VERSION "created by canmatrix"

NS_ :

BS_:

BU_: TBOX FC_Public VCU GW APA

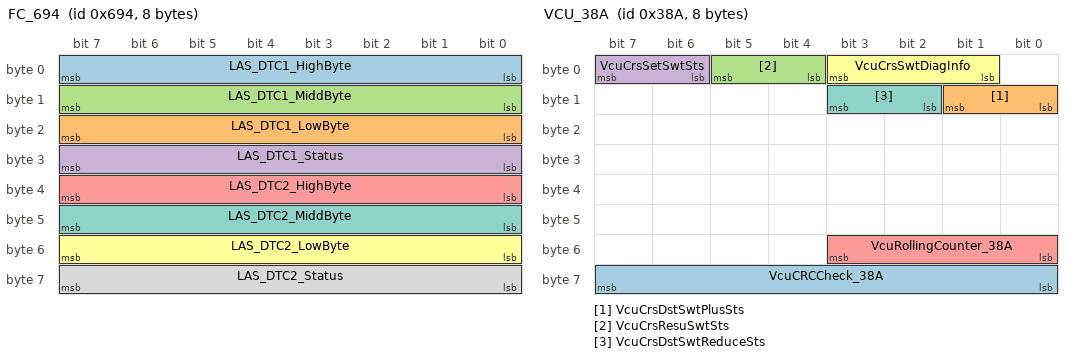
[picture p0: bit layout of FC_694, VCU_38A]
BO_ 1684 FC_694: 8 FC_Public
 SG_ LAS_DTC1_HighByte : 7|8@0+ (1,0) [0|255] "" TBOX
 SG_ LAS_DTC1_LowByte : 23|8@0+ (1,0) [0|255] "" TBOX
 SG_ LAS_DTC1_MiddByte : 15|8@0+ (1,0) [0|255] "" TBOX
 SG_ LAS_DTC1_Status : 31|8@0+ (1,0) [0|255] "" TBOX
 SG_ LAS_DTC2_HighByte : 39|8@0+ (1,0) [0|255] "" TBOX
 SG_ LAS_DTC2_LowByte : 55|8@0+ (1,0) [0|255] "" TBOX
 SG_ LAS_DTC2_MiddByte : 47|8@0+ (1,0) [0|255] "" TBOX
 SG_ LAS_DTC2_Status : 63|8@0+ (1,0) [0|255] "" TBOX

BO_ 759 TBOX_2F7: 64 TBOX
 SG_ TboxLocalTiDate : 20|5@0+ (1,0) [0|31] "day" FC_Public
 SG_ TboxLocalTiHr : 28|5@0+ (1,0) [0|31] "hour" FC_Public
 SG_ TboxLocalTiMins : 37|6@0+ (1,0) [0|63] "minute" FC_Public
 SG_ TboxLocalTiMth : 11|4@0+ (1,0) [0|15] "month" FC_Public
 SG_ TboxLocalTiSec : 45|6@0+ (1,0) [0|63] "second" FC_Public
 SG_ TboxLocalTiVld : 46|1@0+ (1,0) [0|1] "" FC_Public
 SG_ TboxLocalTiYear : 7|8@0+ (1,2000) [2000|2255] "year" FC_Public

BO_ 353 VCU_161: 64 VCU
 SG_ VCUAccPedShield : 7|1@0+ (1,0) [0|1] "" FC_Public
 SG_ VCUAPAdriverInterruption : 6|2@0+ (1,0) [0|3] "" FC_Public
 SG_ VCUAPARequestEnable : 4|2@0+ (1,0) [0|3] "" FC_Public
 SG_ VCUShiftPostionValid : 2|1@0+ (1,0) [0|1] "" FC_Public
 SG_ VcuAccrMod : 1|3@0+ (1,0) [0|7] "" FC_Public
 SG_ VcuAccrPedlPosn : 14|10@0+ (0.1,0) [0|102.3] "%" FC_Public
 SG_ VcuAccrPedlPosnVld : 20|1@0+ (1,0) [0|1] "" FC_Public
 SG_ VcuAPATorqRequestAvailable : 19|1@0+ (1,0) [0|1] "" FC_Public
 SG_ VcuCalcnAccrPedlPosn : 18|10@0+ (0.1,0) [0|102.3] "%" FC_Public
 SG_ VcuCalcnAccrPedlPosnVld : 24|1@0+ (1,0) [0|1] "" FC_Public
 SG_ VcuComFltSts : 39|2@0+ (1,0) [0|3] "" FC_Public
 SG_ VcuEnyRecyclMod : 37|7@0+ (1,0) [0|127] "" FC_Public
 SG_ VcuGearPosn : 65|3@0+ (1,0) [0|7] "" FC_Public
 SG_ VcuOvrdModReq : 78|1@0+ (1,0) [0|1] "" FC_Public
 SG_ VcuPtTqLimMax : 87|16@0+ (1,-32768) [-32768|32767] "Nm" FC_Public
 SG_ VcuPtTqLimMaxVld : 77|1@0+ (1,0) [0|1] "" FC_Public
 SG_ VcuPtTqLimMin : 103|16@0+ (1,-32768) [-32768|32767] "Nm" FC_Public
 SG_ VcuPtTqLimMinVld : 76|1@0+ (1,0) [0|1] "" FC_Public
 SG_ VcuPtTqReal : 135|16@0+ (1,-32768) [-32768|32767] "Nm" FC_Public
 SG_ VcuPtTqRealVld : 75|1@0+ (1,0) [0|1] "" FC_Public
 SG_ VcuPtTqReqAvl : 74|2@0+ (1,0) [0|3] "" FC_Public
 SG_ VcuRdySts : 151|1@0+ (1,0) [0|1] "" FC_Public
 SG_ VcuShiftLvlPosn : 119|4@0+ (1,0) [0|15] "" FC_Public
 SG_ VcuVehGearPosnVld : 150|1@0+ (1,0) [0|1] "" FC_Public
 SG_ VcuVehWhlReqTq : 159|16@0+ (1,-32768) [-32768|32767] "Nm" FC_Public
 SG_ VcuVehWhlReqTqVld : 149|1@0+ (1,0) [0|1] "" FC_Public
 SG_ VcuCrcChk161 : 503|16@0+ (1,0) [0|65535] "" FC_Public
 SG_ VcuCycCntr161 : 491|4@0+ (1,0) [0|15] "" FC_Public

BO_ 906 VCU_38A: 8 VCU
 SG_ VcuCRCCheck_38A : 63|8@0+ (1,0) [0|255] "" FC_Public
 SG_ VcuCrsDstSwtPlusSts : 9|2@0+ (1,0) [0|3] "" FC_Public
 SG_ VcuCrsResuSwtSts : 5|2@0+ (1,0) [0|3] "" FC_Public
 SG_ VcuCrsSetSwtSts : 7|2@0+ (1,0) [0|3] "" FC_Public
 SG_ VcuRollingCounter_38A : 51|4@0+ (1,0) [0|15] "" FC_Public
 SG_ VcuCrsSwtDiagInfo : 3|3@0+ (1,0) [0|7] "" FC_Public
 SG_ VcuCrsDstSwtReduceSts : 11|2@0+ (1,0) [0|3] "" FC_Public

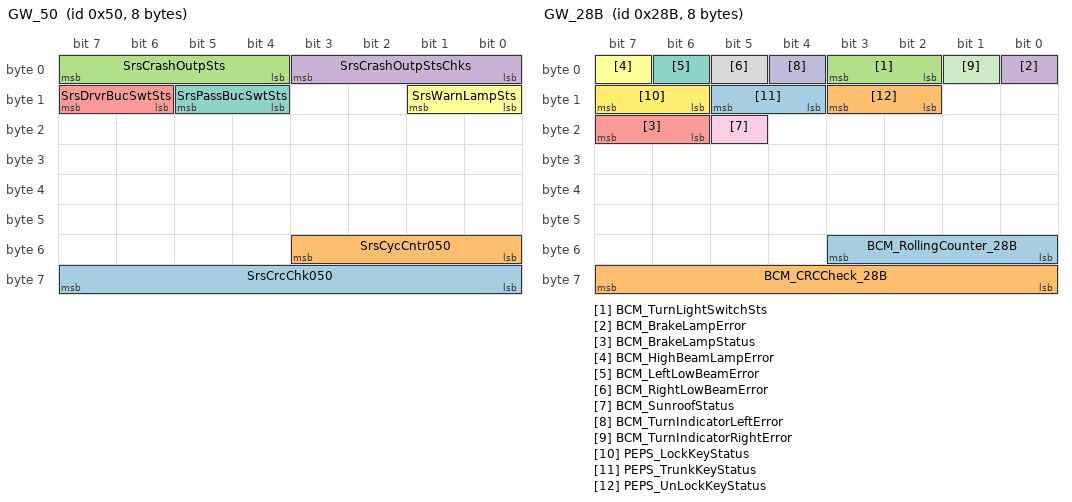
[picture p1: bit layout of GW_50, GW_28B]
BO_ 80 GW_50: 8 GW
 SG_ SrsCrcChk050 : 63|8@0+ (1,0) [0|255] "" FC_Public
 SG_ SrsCycCntr050 : 51|4@0+ (1,0) [0|15] "" FC_Public
 SG_ SrsCrashOutpSts : 7|4@0+ (1,0) [0|15] "" FC_Public
 SG_ SrsCrashOutpStsChks : 3|4@0+ (1,0) [0|15] "" FC_Public
 SG_ SrsDrvrBucSwtSts : 15|2@0+ (1,0) [0|3] "" FC_Public
 SG_ SrsWarnLampSts : 9|2@0+ (1,0) [0|3] "" FC_Public
 SG_ SrsPassBucSwtSts : 13|2@0+ (1,0) [0|3] "" FC_Public

BO_ 648 GW_288: 8 GW
 SG_ BcmAutHeadLiSts : 16|1@0+ (1,0) [0|1] "" FC_Public
 SG_ BcmCrcChk288 : 63|8@0+ (1,0) [0|255] "" FC_Public
 SG_ BcmCycCntr288 : 51|4@0+ (1,0) [0|15] "" FC_Public
 SG_ BcmDrvrDoorSts : 23|1@0+ (1,0) [0|1] "" FC_Public
 SG_ BcmFrntFogLmpSts : 3|2@0+ (1,0) [0|3] "" FC_Public
 SG_ BcmFrntWiperSts : 47|2@0+ (1,0) [0|3] "" FC_Public
 SG_ BcmHiBeamSts : 5|2@0+ (1,0) [0|3] "" FC_Public
 SG_ BcmLeReDoorSts : 21|1@0+ (1,0) [0|1] "" FC_Public
 SG_ BcmLoBeamSts : 7|2@0+ (1,0) [0|3] "" FC_Public
 SG_ BcmPassDoorSts : 22|1@0+ (1,0) [0|1] "" FC_Public
 SG_ BcmReFoglmpSts : 1|2@0+ (1,0) [0|3] "" FC_Public
 SG_ BcmRiReDoorSts : 20|1@0+ (1,0) [0|1] "" FC_Public
 SG_ BcmStsRainSnsr : 54|1@0+ (1,0) [0|1] "" FC_Public
 SG_ BcmTurnIndcrLe : 15|2@0+ (1,0) [0|3] "" FC_Public
 SG_ BcmTurnIndcrRi : 13|2@0+ (1,0) [0|3] "" FC_Public
 SG_ BcmLiSnsrFlt : 45|1@0+ (1,0) [0|1] "" FC_Public
 SG_ BcmEmgyLiSts : 37|2@0+ (1,0) [0|3] "" FC_Public
 SG_ BcmPwrStsFb : 43|2@0+ (1,0) [0|3] "" FC_Public

BO_ 651 GW_28B: 8 GW
 SG_ BCM_RollingCounter_28B : 51|4@0+ (1,0) [0|15] "" FC_Public
 SG_ BCM_CRCCheck_28B : 63|8@0+ (1,0) [0|255] "" FC_Public
 SG_ BCM_TurnLightSwitchSts : 3|2@0+ (1,0) [0|3] "" FC_Public
 SG_ BCM_BrakeLampError : 0|1@0+ (1,0) [0|1] "" FC_Public
 SG_ BCM_BrakeLampStatus : 23|2@0+ (1,0) [0|3] "" FC_Public
 SG_ BCM_HighBeamLampError : 7|1@0+ (1,0) [0|1] "" FC_Public
 SG_ BCM_LeftLowBeamError : 6|1@0+ (1,0) [0|1] "" FC_Public
 SG_ BCM_RightLowBeamError : 5|1@0+ (1,0) [0|1] "" FC_Public
 SG_ BCM_SunroofStatus : 21|1@0+ (1,0) [0|1] "" FC_Public
 SG_ BCM_TurnIndicatorLeftError : 4|1@0+ (1,0) [0|1] "" FC_Public
 SG_ BCM_TurnIndicatorRightError : 1|1@0+ (1,0) [0|1] "" FC_Public
 SG_ PEPS_LockKeyStatus : 15|2@0+ (1,0) [0|3] "" FC_Public
 SG_ PEPS_TrunkKeyStatus : 13|2@0+ (1,0) [0|3] "" FC_Public
 SG_ PEPS_UnLockKeyStatus : 11|2@0+ (1,0) [0|3] "" FC_Public

BO_ 680 GW_2A8: 64 GW
 SG_ TmsActPwr : 18|11@0+ (0.01,0) [0|20.47] "kW" FC_Public
 SG_ TmsAcEnvtlT : 39|8@0+ (0.5,-40) [-40|87.5] "℃" FC_Public
 SG_ TmsAcEnvtlTVld : 432|1@0+ (1,0) [0|1] "" FC_Public
 SG_ TmsFrntBlowMod : 186|3@0+ (1,0) [0|7] "" FC_Public
 SG_ TmsCrcChk2A8 : 503|16@0+ (1,0) [0|65535] "" FC_Public
 SG_ TmsCycCntr2A8 : 491|4@0+ (1,0) [0|15] "" FC_Public

BO_ 722 GW_2D2: 64 GW
 SG_ CdcTotMilg : 399|24@0+ (0.1,0) [0|1677721.5] "Km" FC_Public

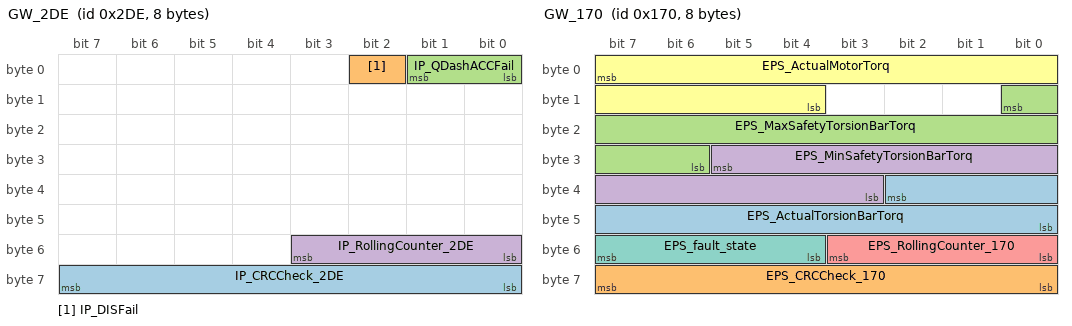
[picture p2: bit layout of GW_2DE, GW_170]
BO_ 734 GW_2DE: 8 GW
 SG_ IP_CRCCheck_2DE : 63|8@0+ (1,0) [0|255] "" FC_Public
 SG_ IP_DISFail : 2|1@0+ (1,0) [0|1] "" FC_Public
 SG_ IP_QDashACCFail : 1|2@0+ (1,0) [0|3] "" FC_Public
 SG_ IP_RollingCounter_2DE : 51|4@0+ (1,0) [0|15] "" FC_Public

BO_ 378 GW_17A: 64 GW
 SG_ EspVehSpdVld : 37|1@0+ (1,0) [0|1] "" FC_Public
 SG_ WheelPressureRearRight_Model : 119|12@0+ (0.1,0) [0|250] "bar" FC_Public
 SG_ WheelPressureFrontRight_Model : 95|12@0+ (0.1,0) [0|250] "bar" FC_Public
 SG_ WheelPressureRearLeft_Model : 99|12@0+ (0.1,0) [0|250] "bar" FC_Public
 SG_ WheelPressureFrontLeft_Model : 467|12@0+ (0.1,0) [0|250] "bar" FC_Public
 SG_ ESP_RollingCounter_17A : 491|4@0+ (1,0) [0|15] "" FC_Public
 SG_ ESP_CRCCheck_17A : 503|16@0+ (1,0) [0|65535] "" FC_Public
 SG_ EPB_APArequest_Available : 64|1@0+ (1,0) [0|1] "" FC_Public
 SG_ EPB_FailStatuss_Primary : 87|2@0+ (1,0) [0|3] "" FC_Public
 SG_ EPB_AchievedClampForce_Primary : 69|5@0+ (1,0) [0|31] "KN" FC_Public
 SG_ EPB_AchievedClampForce : 85|5@0+ (1,0) [0|31] "KN" FC_Public
 SG_ EspVehSpd : 36|13@0+ (0.05625,0) [0|460.74375] "km/h" FC_Public

BO_ 706 GW_2C2: 64 GW
 SG_ IBCU_PFSBrakePressure : 159|12@0+ (0.1,0) [0|250] "bar" FC_Public
 SG_ IBCU_PlungerBrakePressure : 175|12@0+ (0.1,0) [0|250] "bar" FC_Public
 SG_ IBBrkPedlModSts : 52|8@0+ (1,0) [0|255] "" FC_Public
 SG_ IbBrkPedlStsGb : 7|8@0+ (1,0) [0|255] "%" FC_Public
 SG_ IbBrkPedlStsGbVld : 15|2@0+ (1,0) [0|2] "" FC_Public
 SG_ IbCrcChk2C2 : 503|16@0+ (1,0) [0|65535] "" FC_Public
 SG_ IbCycCntr2C2 : 491|4@0+ (1,0) [0|15] "" FC_Public
 SG_ IBCU_PFSBrakePressureValid : 163|1@0+ (1,0) [0|1] "" FC_Public
 SG_ IBCU_PlungerBrakePressureValid : 179|1@0+ (1,0) [0|1] "" FC_Public
 SG_ IBBrkPedlModSwtAvl : 53|1@0+ (1,0) [0|1] "" FC_Public

BO_ 450 GW_1C2: 64 GW
 SG_ EspEbdFailr : 87|1@0+ (1,0) [0|1] "" FC_Public
 SG_ EspAbsActv : 72|1@0+ (1,0) [0|1] "" FC_Public
 SG_ EspAbsFailr : 73|1@0+ (1,0) [0|1] "" FC_Public
 SG_ EspActvSts : 55|1@0+ (1,0) [0|1] "" FC_Public
 SG_ EspFctOpenSts : 54|1@0+ (1,0) [0|1] "" FC_Public
 SG_ EspTcsFailr : 53|1@0+ (1,0) [0|1] "" FC_Public
 SG_ EspReWhlDecTarTqActv : 38|1@0+ (1,0) [0|1] "" FC_Public
 SG_ EspReWhlIncTarTqActv : 37|1@0+ (1,0) [0|1] "" FC_Public
 SG_ EspVehStandstill : 351|1@0+ (1,0) [0|1] "" FC_Public
 SG_ EspReWhlDecTarTq : 271|16@0+ (1,-32768) [-32768|32767] "Nm" FC_Public
 SG_ MbRgnTarWhl : 423|16@0+ (1,-32768) [-32768|32766] "Nm" FC_Public
 SG_ MbRgnTarWhlQlfr : 413|2@0+ (1,0) [0|3] "" FC_Public
 SG_ EspReWhlIncTarTq : 335|16@0+ (1,-32768) [-32768|32767] "Nm" FC_Public
 SG_ EspAutoHoldActvSts : 353|2@0+ (1,0) [0|3] "" FC_Public
 SG_ IBCU_BrakeDiscHighTempWarning : 390|2@0+ (1,0) [0|3] "" FC_Public
 SG_ EspCrcChk1C2 : 503|16@0+ (1,0) [0|65535] "" FC_Public
 SG_ EspCycCntr1C2 : 491|4@0+ (1,0) [0|15] "" FC_Public
 SG_ EspBrkLiOnReq : 397|2@0+ (1,0) [0|3] "" FC_Public
 SG_ EspVdcActvSts : 414|1@0+ (1,0) [0|1] "" FC_Public
 SG_ EspTcsActvSts : 52|1@0+ (1,0) [0|1] "" FC_Public
 SG_ IBCU_ADCReducedFuncAvail : 487|2@0+ (1,0) [0|3] "" FC_Public
 SG_ IBCU_ADCFullFuncAvail : 485|2@0+ (1,0) [0|3] "" FC_Public
 SG_ IBCU_CommunicationInvalid : 483|2@0+ (1,0) [0|3] "" FC_Public
 SG_ IBCU_ADCActiveState : 481|2@0+ (1,0) [0|3] "" FC_Public

BO_ 523 GW_20B: 64 GW
 SG_ ESP_BrakeForce : 263|1@0+ (1,0) [0|1] "" FC_Public
 SG_ ESP_PrefillActive : 260|1@0+ (1,0) [0|1] "" FC_Public
 SG_ ESP_PrefillAvailable : 259|1@0+ (1,0) [0|1] "" FC_Public
 SG_ IBCU_APCActiveStatus : 33|2@0+ (1,0) [0|3] "" FC_Public
 SG_ IBCU_APCReducedFuncAvail : 276|1@0+ (1,0) [0|1] "" FC_Public
 SG_ IBCU_APCFullFuncAvail : 281|2@0+ (1,0) [0|3] "" FC_Public
 SG_ ESP_APA_CDDAPVehicleHold : 283|1@0+ (1,0) [0|1] "" FC_Public
 SG_ ESP_APA_DriverOverride : 119|1@0+ (1,0) [0|1] "" FC_Public
 SG_ ESP_ABAactive : 262|1@0+ (1,0) [0|1] "" FC_Public
 SG_ ESP_ABAavailable : 261|1@0+ (1,0) [0|1] "" FC_Public
 SG_ ESP_AEBAvailable : 258|1@0+ (1,0) [0|1] "" FC_Public
 SG_ ESP_AEBdecActive : 257|1@0+ (1,0) [0|1] "" FC_Public
 SG_ ESP_AWBactive : 256|1@0+ (1,0) [0|1] "" FC_Public
 SG_ ESP_AWBavailable : 271|1@0+ (1,0) [0|1] "" FC_Public
 SG_ ESP_BrakeOverHeatBrakeDiscTemp : 270|1@0+ (1,0) [0|1] "" FC_Public
 SG_ ESP_QDCACC : 279|2@0+ (1,0) [0|3] "" FC_Public
 SG_ WhlSpdFrntLePls : 215|8@0+ (1,0) [0|254] "" FC_Public
 SG_ WhlSpdFrntRiPls : 223|8@0+ (1,0) [0|254] "" FC_Public
 SG_ WhlSpdReLePls : 239|8@0+ (1,0) [0|254] "" FC_Public
 SG_ WhlSpdReRiPls : 231|8@0+ (1,0) [0|254] "" FC_Public
 SG_ WhlSpdLeFrntDir : 22|2@0+ (1,0) [0|3] "" FC_Public
 SG_ WhlSpdLeReDir : 86|2@0+ (1,0) [0|3] "" FC_Public
 SG_ WhlSpdRiFrntDir : 6|2@0+ (1,0) [0|3] "" FC_Public
 SG_ WhlSpdRiReDir : 70|2@0+ (1,0) [0|3] "" FC_Public
 SG_ WhlSpdLeFrntData : 20|13@0+ (0.05625,0) [0|360] "km/h" FC_Public
 SG_ WhlSpdLeFrntDataVld : 23|1@0+ (1,0) [0|1] "" FC_Public
 SG_ WhlSpdLeReData : 84|13@0+ (0.05625,0) [0|360] "km/h" FC_Public
 SG_ WhlSpdLeReDataVld : 87|1@0+ (1,0) [0|1] "" FC_Public
 SG_ WhlSpdRiFrntData : 4|13@0+ (0.05625,0) [0|360] "km/h" FC_Public
 SG_ WhlSpdRiFrntDataVld : 7|1@0+ (1,0) [0|1] "" FC_Public
 SG_ WhlSpdRiReData : 68|13@0+ (0.05625,0) [0|360] "km/h" FC_Public
 SG_ WhlSpdRiReDataVld : 71|1@0+ (1,0) [0|1] "" FC_Public
 SG_ ESP_UrgencyBrakeAlarm : 118|1@0+ (1,0) [0|1] "" FC_Public
 SG_ ESP_CDD_Active : 269|1@0+ (1,0) [0|1] "" FC_Public
 SG_ ESP_CDD_Available : 268|1@0+ (1,0) [0|1] "" FC_Public
 SG_ IbcuCrcChk20B : 503|16@0+ (1,0) [0|65535] "" APA,FC_Public
 SG_ IbcuCycCntr20B : 491|4@0+ (1,0) [0|15] "" APA,FC_Public
 SG_ IBCU_ADCRampOffSuspendState : 493|2@0+ (1,0) [0|3] "" FC_Public
 SG_ ESP_Vehicle_Speed_Reference : 103|13@0+ (0.05625,0) [0|360] "km/h" FC_Public

BO_ 962 GW_3C2: 64 GW
 SG_ EpbFailrSts : 1|2@0+ (1,0) [0|3] "" FC_Public
 SG_ EpbSts : 7|3@0+ (1,0) [0|7] "" FC_Public
 SG_ EspCrcChk3C2 : 503|16@0+ (1,0) [0|65535] "" FC_Public
 SG_ EspCycCntr3C2 : 491|4@0+ (1,0) [0|15] "" FC_Public
 SG_ EspEpbReqAvl : 28|1@0+ (1,0) [0|1] "" FC_Public
 SG_ EpbStsPrimary : 79|3@0+ (1,0) [0|7] "" FC_Public

BO_ 368 GW_170: 8 GW
 SG_ EPS_ActualTorsionBarTorq : 34|11@0+ (0.02,-20.48) [-20.48|20.44] "Nm" FC_Public
 SG_ EPS_CRCCheck_170 : 63|8@0+ (1,0) [0|255] "" FC_Public
 SG_ EPS_MaxSafetyTorsionBarTorq : 8|11@0+ (0.02,-20.48) [-20.48|20.44] "Nm" FC_Public
 SG_ EPS_MinSafetyTorsionBarTorq : 29|11@0+ (0.02,-20.48) [-20.48|20.44] "Nm" FC_Public
 SG_ EPS_RollingCounter_170 : 51|4@0+ (1,0) [0|15] "" FC_Public
 SG_ EPS_ActualMotorTorq : 7|12@0+ (0.01,-20.48) [-20.48|20.46] "Nm" FC_Public
 SG_ EPS_fault_state : 55|4@0+ (1,0) [0|15] "" FC_Public

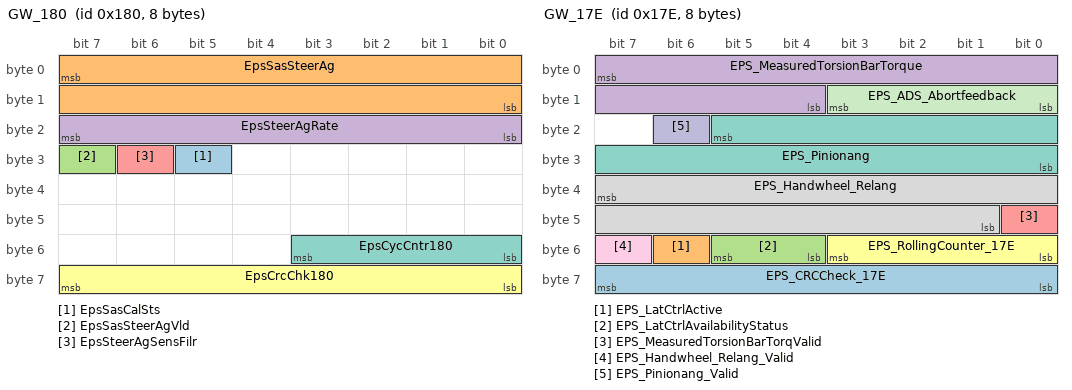
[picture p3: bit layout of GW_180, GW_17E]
BO_ 384 GW_180: 8 GW
 SG_ EpsSasCalSts : 29|1@0+ (1,0) [0|1] "" FC_Public
 SG_ EpsSasSteerAg : 7|16@0- (0.1,0) [-780|780] "degree" FC_Public
 SG_ EpsSasSteerAgVld : 31|1@0+ (1,0) [0|1] "" FC_Public
 SG_ EpsSteerAgRate : 23|8@0+ (4,0) [0|1016] "deg/s" FC_Public
 SG_ EpsSteerAgSensFilr : 30|1@0+ (1,0) [0|1] "" FC_Public
 SG_ EpsCrcChk180 : 63|8@0+ (1,0) [0|255] "" FC_Public
 SG_ EpsCycCntr180 : 51|4@0+ (1,0) [0|15] "" FC_Public

BO_ 382 GW_17E: 8 GW
 SG_ EPS_CRCCheck_17E : 63|8@0+ (1,0) [0|255] "" FC_Public
 SG_ EPS_LatCtrlActive : 54|1@0+ (1,0) [0|1] "" FC_Public
 SG_ EPS_LatCtrlAvailabilityStatus : 53|2@0+ (1,0) [0|3] "" FC_Public
 SG_ EPS_MeasuredTorsionBarTorque : 7|12@0+ (0.01,-20.48) [-20.48|20.46] "Nm" FC_Public
 SG_ EPS_MeasuredTorsionBarTorqValid : 40|1@0+ (1,0) [0|1] "" FC_Public
 SG_ EPS_RollingCounter_17E : 51|4@0+ (1,0) [0|15] "" FC_Public
 SG_ EPS_Pinionang : 21|14@0+ (0.1,-720) [-720|720] "degree" FC_Public
 SG_ EPS_Handwheel_Relang : 39|15@0+ (0.1,-1080) [-1080|1080] "degree" FC_Public
 SG_ EPS_Handwheel_Relang_Valid : 55|1@0+ (1,0) [0|1] "" FC_Public
 SG_ EPS_Pinionang_Valid : 22|1@0+ (1,0) [0|1] "" FC_Public
 SG_ EPS_ADS_Abortfeedback : 11|4@0+ (1,0) [0|15] "" FC_Public

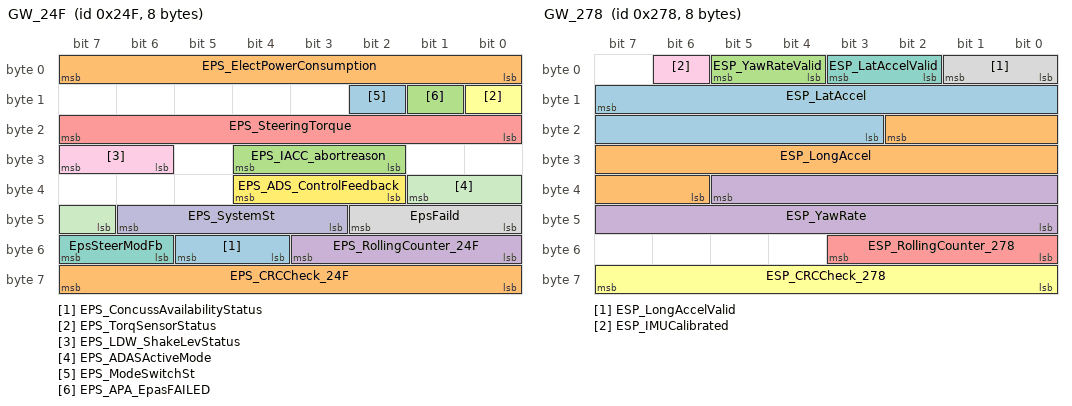
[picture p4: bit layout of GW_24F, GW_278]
BO_ 591 GW_24F: 8 GW
 SG_ EPS_ConcussAvailabilityStatus : 53|2@0+ (1,0) [0|3] "" FC_Public
 SG_ EPS_CRCCheck_24F : 63|8@0+ (1,0) [0|255] "" FC_Public
 SG_ EPS_IACC_abortreason : 28|3@0+ (1,0) [0|7] "" FC_Public
 SG_ EPS_RollingCounter_24F : 51|4@0+ (1,0) [0|15] "" FC_Public
 SG_ EPS_SteeringTorque : 23|8@0+ (0.1794,-22.78) [-22.78|22.78] "Nm" FC_Public
 SG_ EPS_TorqSensorStatus : 8|1@0+ (1,0) [0|1] "" FC_Public
 SG_ EpsSteerModFb : 55|2@0+ (1,0) [0|3] "" FC_Public
 SG_ EpsFaild : 42|3@0+ (1,0) [0|7] "" FC_Public
 SG_ EPS_LDW_ShakeLevStatus : 31|2@0+ (1,0) [0|3] "" FC_Public
 SG_ EPS_SystemSt : 46|4@0+ (1,0) [0|15] "" FC_Public
 SG_ EPS_ADASActiveMode : 33|3@0+ (1,0) [0|7] "" FC_Public
 SG_ EPS_ADS_ControlFeedback : 36|3@0+ (1,0) [0|7] "" FC_Public
 SG_ EPS_ModeSwitchSt : 10|1@0+ (1,0) [0|1] "" FC_Public
 SG_ EPS_ElectPowerConsumption : 7|8@0+ (0.5,0) [0|127] "A" FC_Public
 SG_ EPS_APA_EpasFAILED : 9|1@0+ (1,0) [0|1] "" FC_Public

BO_ 580 FC_244: 64 FC_Public
 SG_ ACC_AccTrqReq : 89|15@0+ (1,-16384) [-16384|16383] "Nm" Vector__XXX
 SG_ ACC_AccTrqReqActive : 106|1@0+ (1,0) [0|1] "" Vector__XXX
 SG_ ACC_LatTakeoverReq : 419|2@0+ (1,0) [0|3] "" Vector__XXX
 SG_ ACC_ACCMode : 54|3@0+ (1,0) [0|7] "" Vector__XXX
 SG_ ACC_ACCTargetAcceleration : 7|8@0+ (0.05,-5) [-10|2.75] "m/s2" Vector__XXX
 SG_ ACC_CDDActive : 44|1@0+ (1,0) [0|1] "" Vector__XXX
 SG_ ACC_CRCCheck_24E : 63|8@0+ (1,0) [0|255] "" Vector__XXX
 SG_ ACC_CRCCheck_25E : 127|8@0+ (1,0) [0|255] "" Vector__XXX
 SG_ ACC_DecToStop : 31|1@0+ (1,0) [0|1] "" Vector__XXX
 SG_ ACC_Driveoff_Request : 55|1@0+ (1,0) [0|1] "" Vector__XXX
 SG_ ACC_RollingCounter_24E : 51|4@0+ (1,0) [0|15] "" Vector__XXX
 SG_ ACC_RollingCounter_25E : 115|4@0+ (1,0) [0|15] "" Vector__XXX
 SG_ ADS_RollingCounter_244 : 427|4@0+ (1,0) [0|15] "" Vector__XXX
 SG_ ADS_CRCCheck_244 : 439|16@0+ (1,0) [0|65535] "" Vector__XXX
 SG_ ACC_LngTakeOverReq : 421|2@0+ (1,0) [0|3] "" Vector__XXX
 SG_ ACC_AWBlevel : 83|4@0+ (1,0) [0|15] "" Vector__XXX
 SG_ ACC_TakeOverReq : 142|2@0+ (1,0) [0|3] "" Vector__XXX

BO_ 786 FC_312: 64 FC_Public
 SG_ ADS_RollingCounter_312 : 491|4@0+ (1,0) [0|15] "" Vector__XXX
 SG_ ADS_CRCCheck_312 : 503|16@0+ (1,0) [0|65535] "" Vector__XXX
 SG_ ACC_ACCTargetID : 6|4@0+ (1,0) [0|15] "" Vector__XXX
 SG_ ACC_CRCCheck_3E4 : 63|8@0+ (1,0) [0|255] "" Vector__XXX
 SG_ ACC_RollingCounter_3E4 : 51|4@0+ (1,0) [0|15] "" Vector__XXX

BO_ 794 FC_31A: 64 FC_Public
 SG_ ACC_DriverHandsOffStatus : 137|2@0+ (1,0) [0|3] "" Vector__XXX
 SG_ ACC_HandsOnReq : 130|3@0+ (1,0) [0|7] "" Vector__XXX
 SG_ ACC_HostLaneLeftStatus : 83|4@0+ (1,0) [0|15] "" Vector__XXX
 SG_ ACC_HostLaneRightStatus : 87|4@0+ (1,0) [0|15] "" Vector__XXX
 SG_ ACC_IACCHWAMode : 135|3@0+ (1,0) [0|7] "" Vector__XXX
 SG_ ACC_IACCHWATextInfoForDriver : 143|5@0+ (1,0) [0|31] "" Vector__XXX
 SG_ ACC_RollingCounter_30D : 179|4@0+ (1,0) [0|15] "" Vector__XXX
 SG_ ACC_CRCCheck_30D : 191|8@0+ (1,0) [0|255] "" Vector__XXX
 SG_ ACC_RollingCounter_367 : 243|4@0+ (1,0) [0|15] "" Vector__XXX
 SG_ ACC_CRCCheck_367 : 255|8@0+ (1,0) [0|255] "" Vector__XXX
 SG_ ACC_RollingCounter_36D : 51|4@0+ (1,0) [0|15] "" Vector__XXX
 SG_ ACC_CRCCheck_36D : 63|8@0+ (1,0) [0|255] "" Vector__XXX
 SG_ ACC_TargetBasedLateralControl : 150|2@0+ (1,0) [0|3] "" Vector__XXX
 SG_ ACC_Voiceinfo : 47|5@0+ (1,0) [0|31] "" Vector__XXX
 SG_ ACC_RollingCounter_31A : 491|4@0+ (1,0) [0|15] "" Vector__XXX
 SG_ ACC_CRCCheck_31A : 503|16@0+ (1,0) [0|65535] "" Vector__XXX
 SG_ ACC_RollingCounter_30A : 115|4@0+ (1,0) [0|15] "" Vector__XXX
 SG_ ACC_CRCCheck_30A : 127|8@0+ (1,0) [0|255] "" Vector__XXX
 SG_ ACC_EmergencyLightingRequest : 148|2@0+ (1,0) [0|3] "" Vector__XXX

BO_ 775 FC_307: 64 FC_Public
 SG_ ACC_RollingCounter_307 : 491|4@0+ (1,0) [0|15] "" Vector__XXX
 SG_ ACC_CRCCheck_307 : 503|16@0+ (1,0) [0|65535] "" Vector__XXX
 SG_ ACC_ACCEPBrequest : 23|1@0+ (1,0) [0|1] "" Vector__XXX
 SG_ ACC_ACCTargetDirection : 104|3@0+ (1,0) [0|7] "" Vector__XXX
 SG_ ACC_ACCTargetLatRange : 99|10@0+ (0.1,-50) [-50|50] "m" Vector__XXX
 SG_ ACC_ACCTargetLngRange : 71|9@0+ (0.5,-70) [-70|180] "m" Vector__XXX
 SG_ ACC_ACCTargetRelSpd : 92|9@0+ (1,-250) [-250|250] "km/h" Vector__XXX
 SG_ ACC_ACCTargetType : 78|4@0+ (1,0) [0|15] "" Vector__XXX
 SG_ ACC_CRCCheck_322 : 127|8@0+ (1,0) [0|255] "" Vector__XXX
 SG_ ACC_CRCCheck_344 : 191|8@0+ (1,0) [0|255] "" Vector__XXX
 SG_ ACC_CRCCheck_35E : 63|8@0+ (1,0) [0|255] "" Vector__XXX
 SG_ ACC_CRCCheck_35F : 255|8@0+ (1,0) [0|255] "" Vector__XXX
 SG_ ACC_DistanceLevel : 22|3@0+ (1,0) [0|7] "" Vector__XXX
 SG_ ACC_ObjValid : 13|1@0+ (1,0) [0|1] "" Vector__XXX
 SG_ ACC_RollingCounter_322 : 115|4@0+ (1,0) [0|15] "" Vector__XXX
 SG_ ACC_RollingCounter_344 : 179|4@0+ (1,0) [0|15] "" Vector__XXX
 SG_ ACC_RollingCounter_35E : 51|4@0+ (1,0) [0|15] "" Vector__XXX
 SG_ ACC_RollingCounter_35F : 243|4@0+ (1,0) [0|15] "" Vector__XXX
 SG_ ACC_SaftyBelt_Tightened : 41|2@0+ (1,0) [0|3] "" Vector__XXX
 SG_ ACC_SaftyBeltVibrationReq : 42|1@0+ (1,0) [0|1] "" Vector__XXX
 SG_ ACC_SetSpeed : 6|8@0+ (1,0) [0|254] "Km/h" Vector__XXX
 SG_ ACC_TextInfoForDriver : 84|5@0+ (1,0) [0|31] "" Vector__XXX
 SG_ ACC_TimeGapSet : 18|3@0+ (1,0) [0|7] "" Vector__XXX

BO_ 442 FC_1BA: 32 FC_Public
 SG_ ACC_CRCCheck_1BA_0 : 63|8@0+ (1,0) [0|255] "" Vector__XXX
 SG_ ACC_LatAngReq : 17|14@0+ (0.1,-720) [-720|720] "degree" Vector__XXX
 SG_ ACC_LatAngReqActive : 35|1@0+ (1,0) [0|1] "" Vector__XXX
 SG_ ACC_MotorTorqueMaxLimitRequest : 7|11@0+ (0.02,-20.48) [-20.48|20.44] "Nm" Vector__XXX
 SG_ ACC_MotorTorqueMinLimitRequest : 12|11@0+ (0.02,-20.48) [-20.48|20.44] "Nm" Vector__XXX
 SG_ ACC_RollingCounter_1BA_1 : 115|4@0+ (1,0) [0|15] "" Vector__XXX
 SG_ ACC_CRCCheck_1BA_1 : 127|8@0+ (1,0) [0|255] "" Vector__XXX
 SG_ ACC_RollingCounter_1BA_0 : 51|4@0+ (1,0) [0|15] "" Vector__XXX

BO_ 1287 GW_507: 64 GW
 SG_ HU_AutoBrakeEnable : 131|1@0+ (1,0) [0|1] "" FC_Public
 SG_ HU_FCWSetting : 165|3@0+ (1,0) [0|7] "" FC_Public
 SG_ HU_HMAEnable : 12|1@0+ (1,0) [0|1] "" FC_Public
 SG_ HU_IACCEnable : 29|2@0+ (1,0) [0|3] "" FC_Public
 SG_ HU_LASModeSelection : 5|3@0+ (1,0) [0|7] "" FC_Public
 SG_ HU_LASWarningModeSelection : 10|3@0+ (1,0) [0|7] "" FC_Public
 SG_ HU_VC_CruiseControl : 138|3@0+ (1,0) [0|7] "" FC_Public
 SG_ HU_VC_CruiseSetDistance : 142|3@0+ (1,0) [0|7] "" FC_Public
 SG_ HU_VC_CruiseSetSpeed : 151|8@0+ (1,0) [0|255] "" FC_Public

BO_ 957 GW_3BD: 64 GW
 SG_ HU_ELKEnable : 1|2@0+ (1,0) [0|3] "" FC_Public

BO_ 632 GW_278: 8 GW
 SG_ ESP_LatAccel : 15|13@0+ (0.01,-32) [-32|49.91] "m/s2" FC_Public
 SG_ ESP_LongAccel : 18|13@0+ (0.01,-32) [-32|49.91] "m/s2" FC_Public
 SG_ ESP_YawRateValid : 5|2@0+ (1,0) [0|3] "" FC_Public
 SG_ ESP_YawRate : 37|14@0+ (0.01,-81.91) [-81.91|81.92] "degree/s" FC_Public
 SG_ ESP_RollingCounter_278 : 51|4@0+ (1,0) [0|15] "" FC_Public
 SG_ ESP_CRCCheck_278 : 63|8@0+ (1,0) [0|255] "" FC_Public
 SG_ ESP_LatAccelValid : 3|2@0+ (1,0) [0|3] "" FC_Public
 SG_ ESP_LongAccelValid : 1|2@0+ (1,0) [0|3] "" FC_Public
 SG_ ESP_IMUCalibrated : 6|1@0+ (1,0) [0|1] "" FC_Public

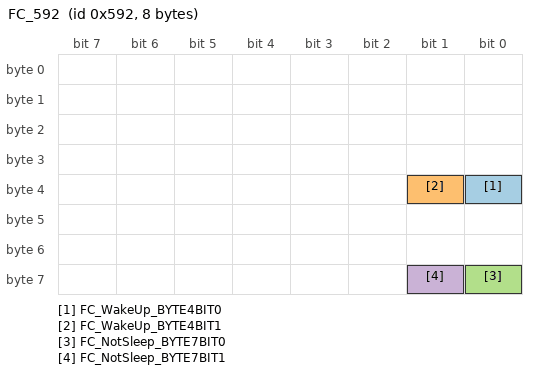
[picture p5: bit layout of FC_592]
BO_ 1426 FC_592: 8 FC_Public
 SG_ FC_WakeUp_BYTE4BIT0 : 32|1@0+ (1,0) [0|1] "" Vector__XXX
 SG_ FC_WakeUp_BYTE4BIT1 : 33|1@0+ (1,0) [0|1] "" Vector__XXX
 SG_ FC_NotSleep_BYTE7BIT0 : 56|1@0+ (1,0) [0|1] "" Vector__XXX
 SG_ FC_NotSleep_BYTE7BIT1 : 57|1@0+ (1,0) [0|1] "" Vector__XXX

BO_ 1393 FC_571: 16 FC_Public
 SG_ FCHwVers0 : 71|8@0+ (1,0) [0|255] "" Vector__XXX
 SG_ FCHwVers1 : 79|8@0+ (1,0) [0|255] "" Vector__XXX
 SG_ FCHwVers2 : 87|8@0+ (1,0) [0|255] "" Vector__XXX
 SG_ FCHwVers3 : 95|8@0+ (1,0) [0|255] "" Vector__XXX
 SG_ FCHwVers4 : 103|16@0+ (1,0) [0|65535] "" Vector__XXX
 SG_ FCHwVers5 : 119|8@0+ (1,0) [0|255] "" Vector__XXX
 SG_ FCHwVers6 : 127|8@0+ (1,0) [0|255] "" Vector__XXX
 SG_ FCSwVers0 : 7|8@0+ (1,0) [0|255] "" Vector__XXX
 SG_ FCSwVers1 : 15|8@0+ (1,0) [0|255] "" Vector__XXX
 SG_ FCSwVers2 : 23|8@0+ (1,0) [0|255] "" Vector__XXX
 SG_ FCSwVers3 : 31|8@0+ (1,0) [0|255] "" Vector__XXX
 SG_ FCSwVers4 : 39|16@0+ (1,0) [0|65535] "" Vector__XXX
 SG_ FCSwVers5 : 55|8@0+ (1,0) [0|255] "" Vector__XXX
 SG_ FCSwVers6 : 63|8@0+ (1,0) [0|255] "" Vector__XXX

BO_ 943 GW_3AF: 64 GW
 SG_ HU_NavCurrentRoadType : 218|3@0+ (1,0) [0|7] "" FC_Public

CM_ SG_ 1684 LAS_DTC1_HighByte "DTC上传";
CM_ SG_ 1684 LAS_DTC1_LowByte "DTC上传";
CM_ SG_ 1684 LAS_DTC1_MiddByte "DTC上传";
CM_ SG_ 1684 LAS_DTC1_Status "DTC上传";
CM_ SG_ 1684 LAS_DTC2_HighByte "DTC上传";
CM_ SG_ 1684 LAS_DTC2_LowByte "DTC上传";
CM_ SG_ 1684 LAS_DTC2_MiddByte "DTC上传";
CM_ SG_ 1684 LAS_DTC2_Status "DTC上传";
CM_ SG_ 353 VcuComFltSts "无相关配置时保留信号默认发0
";
CM_ SG_ 353 VcuShiftLvlPosn "0x5~0xE:Reserved";
CM_ SG_ 906 VcuCRCCheck_38A "CRCCheck_SAE_J1850_2001,多项式采用X8+X4+X3+X2+1";
CM_ SG_ 906 VcuCrsDstSwtPlusSts "/";
CM_ SG_ 906 VcuCrsResuSwtSts "/";
CM_ SG_ 906 VcuCrsSetSwtSts "/";
CM_ SG_ 906 VcuRollingCounter_38A "rolling counter";
CM_ SG_ 906 VcuCrsDstSwtReduceSts "/";
CM_ SG_ 80 SrsCrcChk050 "CRC_8校验，多项式采用X8+X4+X3+X2+1";
CM_ SG_ 80 SrsCrashOutpSts "/";
CM_ SG_ 80 SrsCrashOutpStsChks "Checksum
:(SRS_CrashOutputStatus) XOR 0xF";
CM_ SG_ 80 SrsDrvrBucSwtSts "Default value: 0x0";
CM_ SG_ 80 SrsWarnLampSts "/";
CM_ SG_ 80 SrsPassBucSwtSts "For PDM is configured projects:
(if PDM is configured, logical detection with PDM is required)
0x0: [Buckled] or [Unbuckled and passenger not occupied]
0x1: [Unbuckle and passenger occupied]
0x2: Not Used
0x3: Not Used
";
CM_ SG_ 648 BcmCrcChk288 "CRCCheck_SAE_J1850_2001,多项式采用X8+X4+X3+X2+1";
CM_ SG_ 648 BcmEmgyLiSts "/";
CM_ SG_ 651 BCM_RollingCounter_28B "/";
CM_ SG_ 651 BCM_CRCCheck_28B "/";
CM_ SG_ 651 BCM_TurnLightSwitchSts "/";
CM_ SG_ 651 BCM_BrakeLampError "/";
CM_ SG_ 651 BCM_BrakeLampStatus "/";
CM_ SG_ 651 BCM_LeftLowBeamError "/";
CM_ SG_ 651 BCM_RightLowBeamError "/";
CM_ SG_ 651 BCM_SunroofStatus "/";
CM_ SG_ 651 BCM_TurnIndicatorLeftError "/";
CM_ SG_ 651 BCM_TurnIndicatorRightError "/";
CM_ SG_ 651 PEPS_LockKeyStatus "/";
CM_ SG_ 651 PEPS_TrunkKeyStatus "/";
CM_ SG_ 651 PEPS_UnLockKeyStatus "/";
CM_ SG_ 680 TmsActPwr "空调工作状态";
CM_ SG_ 680 TmsAcEnvtlTVld "/";
CM_ SG_ 680 TmsCrcChk2A8 "16-bit CCITT-FALSE CRC16，多项式1021h
Refer to AUTOSAR <Specification of CRC Routines>";
CM_ SG_ 734 IP_CRCCheck_2DE "CRCCheck_SAE_J1850_2001,多项式采用X8+X4+X3+X2+1";
CM_ SG_ 734 IP_DISFail "GW报文转发";
CM_ SG_ 734 IP_QDashACCFail "GW报文转发";
CM_ SG_ 734 IP_RollingCounter_2DE "rolling counter";
CM_ SG_ 378 EspVehSpdVld "TCU接收为DCT专用";
CM_ SG_ 378 EPB_AchievedClampForce "/";
CM_ SG_ 378 EspVehSpd "TCU接收为DCT专用";
CM_ SG_ 706 IbBrkPedlStsGb "国标RMU需求";
CM_ SG_ 706 IbCrcChk2C2 "校验算法见诊断方案要求";
CM_ SG_ 450 EspVehStandstill "/";
CM_ SG_ 450 EspReWhlIncTarTq "轮端扭矩";
CM_ SG_ 450 EspAutoHoldActvSts "/";
CM_ SG_ 450 EspBrkLiOnReq "/";
CM_ SG_ 523 ESP_BrakeForce "/";
CM_ SG_ 523 ESP_PrefillActive "/";
CM_ SG_ 523 ESP_PrefillAvailable "/";
CM_ SG_ 523 IBCU_APCActiveStatus "/";
CM_ SG_ 523 IBCU_APCReducedFuncAvail "/";
CM_ SG_ 523 IBCU_APCFullFuncAvail "/";
CM_ SG_ 523 ESP_APA_CDDAPVehicleHold "/";
CM_ SG_ 523 ESP_APA_DriverOverride "/";
CM_ SG_ 523 ESP_ABAactive "/";
CM_ SG_ 523 ESP_ABAavailable "/";
CM_ SG_ 523 ESP_AEBAvailable "/";
CM_ SG_ 523 ESP_AEBdecActive "/";
CM_ SG_ 523 ESP_AWBactive "/";
CM_ SG_ 523 ESP_AWBavailable "/";
CM_ SG_ 523 ESP_BrakeOverHeatBrakeDiscTemp "/";
CM_ SG_ 523 ESP_QDCACC "/";
CM_ SG_ 523 WhlSpdFrntLePls "258";
CM_ SG_ 523 WhlSpdFrntRiPls "258";
CM_ SG_ 523 WhlSpdReLePls "258";
CM_ SG_ 523 WhlSpdReRiPls "258";
CM_ SG_ 523 WhlSpdLeFrntDir "206";
CM_ SG_ 523 WhlSpdLeReDir "208";
CM_ SG_ 523 WhlSpdRiFrntDir "206";
CM_ SG_ 523 WhlSpdRiReDir "208";
CM_ SG_ 523 WhlSpdLeFrntData "206";
CM_ SG_ 523 WhlSpdLeFrntDataVld "206";
CM_ SG_ 523 WhlSpdLeReData "208";
CM_ SG_ 523 WhlSpdLeReDataVld "208";
CM_ SG_ 523 WhlSpdRiFrntData "206";
CM_ SG_ 523 WhlSpdRiFrntDataVld "206";
CM_ SG_ 523 WhlSpdRiReData "208";
CM_ SG_ 523 WhlSpdRiReDataVld "208";
CM_ SG_ 523 ESP_UrgencyBrakeAlarm "/";
CM_ SG_ 523 ESP_CDD_Active "/";
CM_ SG_ 523 ESP_CDD_Available "/";
CM_ SG_ 523 ESP_Vehicle_Speed_Reference "0x0~0x1900=0~360km/h；
0x1901～0x1FFE=Reserved；
0x1FFF=Invalid
APA2.0接收";
CM_ SG_ 962 EspCrcChk3C2 "校验算法见诊断方案要求";
CM_ SG_ 368 EPS_ActualTorsionBarTorq "?方向盘左打为正。
?在EPS ECU 开始助力之前、Initial 值输出为(0)。
?异常状态（确定故障）的情况下、Invalid 值输出为(0x7FF)。
平台为10ms，CD569特例为8ms";
CM_ SG_ 368 EPS_CRCCheck_170 "平台为10ms，CD569特例为8ms，CRCCheck_SAE_J1850_2001,多项式采用X8+X4+X3+X2+1";
CM_ SG_ 368 EPS_MaxSafetyTorsionBarTorq "?方向盘左打为正。
?在EPS ECU 开始助力之前、Initial 值输出为(0)。
?异常状态（确定故障）的情况下、Invalid 值输出为(0x7FF)。
平台为10ms，CD569特例为8ms";
CM_ SG_ 368 EPS_MinSafetyTorsionBarTorq "平台为10ms，CD569特例为8ms
?方向盘左打为正。
?在EPS ECU 开始助力之前、Initial 值输出为(0)。
?异常状态（确定故障）的情况下、Invalid 值输出为(0x7FF)。";
CM_ SG_ 368 EPS_RollingCounter_170 "平台为10ms，CD569特例为8ms";
CM_ SG_ 368 EPS_ActualMotorTorq "?方向盘左打为正。
?在EPS ECU 开始助力之前、Initial 值输出为(0)。
?异常状态（确定故障）的情况下、Invalid 值输出为(0x7FF)。";
CM_ SG_ 368 EPS_fault_state "(供应商补充与自驾相关的故障状态)";
CM_ SG_ 384 EpsSasSteerAg "方向盘往零点左转为正，零点右转为负
Steering wheel angle (N : value of the message) :
: N × 0.1 , for 0 < N ≤ 32767
: (N-65536) × 0.1 , for N ＞ 32767
Note:       that Clockwise rotation is ‘-‘ and anti-Clockwise rotation is ‘+‘";
CM_ SG_ 384 EpsSteerAgRate "方向盘往零点左转为正,零点右转为负
SteeringAngleSpeed
(N:valueofthemessage):
:N×4,for0<N≤254
:errorsignaled,forN>254";
CM_ SG_ 384 EpsCrcChk180 "8bitCRCafterSAEJ1850accordingtoscheme(c-code),isgeneratedoverByte0toByte6";
CM_ SG_ 384 EpsCycCntr180 "messagecounter";
CM_ SG_ 382 EPS_CRCCheck_17E "平台为10ms，CD569特例为8ms,CRCCheck_SAE_J1850_2001,多项式采用X8+X4+X3+X2+1";
CM_ SG_ 382 EPS_LatCtrlActive "平台为10ms，CD569特例为8ms";
CM_ SG_ 382 EPS_LatCtrlAvailabilityStatus "平台为10ms，CD569特例为8ms";
CM_ SG_ 382 EPS_MeasuredTorsionBarTorque "?算式：(Measured Torsion Bar Torque – 0x800)*0.01
?方向盘左打为正。
?在EPS ECU 开始助力之前、Initial 值输出为(0)。
?异常状态（确定故障）的情况下、Invalid 值输出为(0xFFF)。";
CM_ SG_ 382 EPS_MeasuredTorsionBarTorqValid "平台为10ms，CD569特例为8ms";
CM_ SG_ 382 EPS_RollingCounter_17E "1.rolling counter
2.平台为10ms，CD569特例为8ms";
CM_ SG_ 382 EPS_Pinionang "方向盘往零点左转为正，零点右转为负
0x384A-3FFF=Reserved";
CM_ SG_ 382 EPS_Handwheel_Relang "方向盘往零点逆时针转为正，零点顺时针转为负
异常状态（确定故障）的情况下)。";
CM_ SG_ 382 EPS_ADS_Abortfeedback " 建议行车泊车分开 ";
CM_ SG_ 591 EPS_CRCCheck_24F "CRCCheck_SAE_J1850_2001,多项式采用X8+X4+X3+X2+1";
CM_ SG_ 591 EPS_APA_EpasFAILED "APA needs";
CM_ SG_ 580 ACC_AccTrqReq "/";
CM_ SG_ 580 ACC_AccTrqReqActive "/";
CM_ SG_ 580 ACC_LatTakeoverReq "/";
CM_ SG_ 580 ACC_ACCMode "/";
CM_ SG_ 580 ACC_ACCTargetAcceleration "ACC target acceleration for transmission.";
CM_ SG_ 580 ACC_CDDActive "/";
CM_ SG_ 580 ACC_CRCCheck_24E "CRCCheck_SAE_J1850_2001,多项式采用X8+X4+X3+X2+1";
CM_ SG_ 580 ACC_CRCCheck_25E "CRCCheck_SAE_J1850_2001,多项式采用X8+X4+X3+X2+1";
CM_ SG_ 580 ACC_DecToStop "/";
CM_ SG_ 580 ACC_Driveoff_Request "/";
CM_ SG_ 580 ACC_RollingCounter_24E "rolling counter";
CM_ SG_ 580 ACC_RollingCounter_25E "rolling counter";
CM_ SG_ 580 ADS_RollingCounter_244 "rolling counter";
CM_ SG_ 580 ADS_CRCCheck_244 "16-bit CCITT-FALSE CRC16，多项式1021h
Refer to AUTOSAR <Specification of CRC Routines>";
CM_ SG_ 580 ACC_LngTakeOverReq "/";
CM_ SG_ 786 ADS_RollingCounter_312 "rolling counter";
CM_ SG_ 786 ADS_CRCCheck_312 "16-bit CCITT-FALSE CRC16，多项式1021h
Refer to AUTOSAR <Specification of CRC Routines>";
CM_ SG_ 786 ACC_ACCTargetID "/";
CM_ SG_ 786 ACC_CRCCheck_3E4 "CRCCheck_SAE_J1850_2001,多项式采用X8+X4+X3+X2+1";
CM_ SG_ 786 ACC_RollingCounter_3E4 "rolling counter";
CM_ SG_ 794 ACC_DriverHandsOffStatus "/";
CM_ SG_ 794 ACC_HandsOnReq "/";
CM_ SG_ 794 ACC_HostLaneLeftStatus "有ACC、LAS时由ACC发送，其余由APA或AVM发送";
CM_ SG_ 794 ACC_HostLaneRightStatus "有ACC、LAS时由ACC发送，其余由APA或AVM发送";
CM_ SG_ 794 ACC_IACCHWAMode "/";
CM_ SG_ 794 ACC_IACCHWATextInfoForDriver "/";
CM_ SG_ 794 ACC_RollingCounter_30D "rolling counter";
CM_ SG_ 794 ACC_CRCCheck_30D "CRCCheck_SAE_J1850_2001,多项式采用X8+X4+X3+X2+1";
CM_ SG_ 794 ACC_RollingCounter_367 "rolling counter";
CM_ SG_ 794 ACC_RollingCounter_36D "rolling counter";
CM_ SG_ 794 ACC_TargetBasedLateralControl "/";
CM_ SG_ 794 ACC_RollingCounter_31A "rolling counter";
CM_ SG_ 794 ACC_CRCCheck_31A "16-bit CCITT-FALSE CRC16，多项式1021h
Refer to AUTOSAR <Specification of CRC Routines>";
CM_ SG_ 794 ACC_RollingCounter_30A "rolling counter";
CM_ SG_ 775 ACC_RollingCounter_307 "rolling counter";
CM_ SG_ 775 ACC_CRCCheck_307 "16-bit CCITT-FALSE CRC16，多项式1021h
Refer to AUTOSAR <Specification of CRC Routines>";
CM_ SG_ 775 ACC_ACCEPBrequest "/";
CM_ SG_ 775 ACC_ACCTargetLatRange "向左为正，向右为负";
CM_ SG_ 775 ACC_ACCTargetLngRange "负数代表向后，正数代表向前，原点为前雷达波束发射面";
CM_ SG_ 775 ACC_ACCTargetRelSpd "前方目标比本车快为正，前方目标比本车慢为负";
CM_ SG_ 775 ACC_ACCTargetType "/";
CM_ SG_ 775 ACC_CRCCheck_322 "CRCCheck_SAE_J1850_2001,多项式采用X8+X4+X3+X2+1";
CM_ SG_ 775 ACC_CRCCheck_344 "CRCCheck_SAE_J1850_2001,多项式采用X8+X4+X3+X2+1";
CM_ SG_ 775 ACC_CRCCheck_35E "CRCCheck_SAE_J1850_2001,多项式采用X8+X4+X3+X2+1";
CM_ SG_ 775 ACC_CRCCheck_35F "CRCCheck_SAE_J1850_2001,多项式采用X8+X4+X3+X2+1";
CM_ SG_ 775 ACC_DistanceLevel "/";
CM_ SG_ 775 ACC_ObjValid "/";
CM_ SG_ 775 ACC_RollingCounter_322 "rolling counter";
CM_ SG_ 775 ACC_RollingCounter_344 "rolling counter";
CM_ SG_ 775 ACC_RollingCounter_35E "rolling counter";
CM_ SG_ 775 ACC_RollingCounter_35F "rolling counter";
CM_ SG_ 775 ACC_SetSpeed "the set speed from driver, should be available
as long as ACC is active.";
CM_ SG_ 775 ACC_TextInfoForDriver "/";
CM_ SG_ 775 ACC_TimeGapSet "/";
CM_ SG_ 442 ACC_CRCCheck_1BA_0 "CRCCheck_SAE_J1850_2001,多项式采用X8+X4+X3+X2+1";
CM_ SG_ 442 ACC_LatAngReq "方向盘往零点左转为正，零点右转为负
0x3841-3FFF:Reserved";
CM_ SG_ 442 ACC_MotorTorqueMaxLimitRequest "?方向盘左打为正。
?在EPS ECU 开始助力之前、Initial 值输出为(0)。
?0x7FF:Reserved";
CM_ SG_ 442 ACC_MotorTorqueMinLimitRequest "?方向盘左打为正。
?在EPS ECU 开始助力之前、Initial 值输出为(0)。
?0x7FF:Reserved";
CM_ SG_ 442 ACC_RollingCounter_1BA_1 "GW报文转发
rolling counter";
CM_ SG_ 442 ACC_CRCCheck_1BA_1 "CRCCheck_SAE_J1850_2001,多项式采用X8+X4+X3+X2+1";
CM_ SG_ 442 ACC_RollingCounter_1BA_0 "GW报文转发
rolling counter";
CM_ SG_ 1287 HU_AutoBrakeEnable "/";
CM_ SG_ 1287 HU_HMAEnable "513(周期)和514(事件)，当前多数项目使用514(事件)报文。";
CM_ SG_ 1287 HU_IACCEnable "513(周期)和514(事件)，当前多数项目使用514(事件)报文。";
CM_ SG_ 1287 HU_LASModeSelection "513(周期)和514(事件)，当前多数项目使用514(事件)报文。";
CM_ SG_ 1287 HU_LASWarningModeSelection "513(周期)和514(事件)，当前多数项目使用514(事件)报文。";
CM_ SG_ 1287 HU_VC_CruiseControl "/";
CM_ SG_ 1287 HU_VC_CruiseSetDistance "/";
CM_ SG_ 1287 HU_VC_CruiseSetSpeed "/";
CM_ SG_ 632 ESP_LatAccel "/";
CM_ SG_ 632 ESP_LongAccel "/";
CM_ SG_ 632 ESP_YawRate "/";
CM_ SG_ 632 ESP_LatAccelValid "/";
CM_ SG_ 632 ESP_LongAccelValid "/";
CM_ SG_ 1426 FC_WakeUp_BYTE4BIT0 "记录第一次唤醒原因，不更新";
CM_ SG_ 1426 FC_WakeUp_BYTE4BIT1 "记录第一次唤醒原因，不更新";
CM_ SG_ 1426 FC_NotSleep_BYTE7BIT0 "实时更新";
CM_ SG_ 1426 FC_NotSleep_BYTE7BIT1 "实时更新";
CM_ SG_ 1393 FCHwVers0 "ASCII码，命名规则按照《QJD T037-2019 汽车产品零部件件号和名称编制规范》";
CM_ SG_ 1393 FCHwVers1 "ASCII码，命名规则按照《QJD T037-2019 汽车产品零部件件号和名称编制规范》";
CM_ SG_ 1393 FCHwVers2 "ASCII码，命名规则按照《QJD T037-2019 汽车产品零部件件号和名称编制规范》";
CM_ SG_ 1393 FCHwVers3 "ASCII码，命名规则按照《QJD T037-2019 汽车产品零部件件号和名称编制规范》";
CM_ SG_ 1393 FCHwVers4 "ASCII码，命名规则按照《QJD T037-2019 汽车产品零部件件号和名称编制规范》";
CM_ SG_ 1393 FCHwVers5 "ASCII码，命名规则按照《QJD T037-2019 汽车产品零部件件号和名称编制规范》";
CM_ SG_ 1393 FCHwVers6 "ASCII码，命名规则按照《QJD T037-2019 汽车产品零部件件号和名称编制规范》";
CM_ SG_ 1393 FCSwVers0 "ASCII码，命名规则按照《QJD T037-2019 汽车产品零部件件号和名称编制规范》";
CM_ SG_ 1393 FCSwVers1 "ASCII码，命名规则按照《QJD T037-2019 汽车产品零部件件号和名称编制规范》";
CM_ SG_ 1393 FCSwVers2 "ASCII码，命名规则按照《QJD T037-2019 汽车产品零部件件号和名称编制规范》";
CM_ SG_ 1393 FCSwVers3 "ASCII码，命名规则按照《QJD T037-2019 汽车产品零部件件号和名称编制规范》";
CM_ SG_ 1393 FCSwVers4 "ASCII码，命名规则按照《QJD T037-2019 汽车产品零部件件号和名称编制规范》";
CM_ SG_ 1393 FCSwVers5 "ASCII码，命名规则按照《QJD T037-2019 汽车产品零部件件号和名称编制规范》";
CM_ SG_ 1393 FCSwVers6 "ASCII码，命名规则按照《QJD T037-2019 汽车产品零部件件号和名称编制规范》";
CM_ SG_ 943 HU_NavCurrentRoadType "1.未搭载ADAS:
0x0:Road Type Unknown:Small road, Walking Street
0x1:Road Type Class 1:Secondary Roads
0x2:Road Type Class 2:Mainly Road in City
0x3:Road Type Class 3:Mainly Road in City, Normal Province Road, Mainly street
0x4:Road Type Class 4:Province Road, Mainly Road
0x5:Road Type Class 5:Highway, National Road, Speed road
0x6~0x7:Reserved
2.搭载ADAS:
0x0:未知
0x1:城市主要道路
0x2:城市快速路
0x3:省道，县道
0x4:国道
0x5:高速路
0x6:次要道路，普通道路，乡公路，县乡内部路
0x7:预留
";

BA_DEF_ BO_ "CANFD_BRS" ENUM  "0","1";
BA_DEF_ BO_ "GenMsgCycleTime" INT 0 50000;
BA_DEF_ BO_ "GenMsgILSupport" ENUM  "no","Yes";
BA_DEF_ BO_ "GenMsgSendType" ENUM  "Cyclic","NotUsed","NotUsed","NotUsed","NotUsed","Cyclic","NotUsed","IfActive","NoMsgSendType","NotUsed","vector_leerstring";
BA_DEF_ BO_ "VFrameFormat" ENUM  "StandardCAN","ExtendedCAN","reserved","reserved","reserved","reserved","reserved","reserved","reserved","reserved","reserved","reserved","reserved","reserved","StandardCAN_FD","ExtendedCAN_FD";
BA_DEF_ SG_ "GenSigStartValue" FLOAT 0 100000000000;
BA_DEF_  "BusType" STRING;
BA_DEF_  "DBName" STRING;
BA_DEF_  "NmBaseAddress" HEX 1024 1087;
BA_DEF_DEF_ "BusType" "";
BA_DEF_DEF_ "CANFD_BRS" "1";
BA_DEF_DEF_ "DBName" "";
BA_DEF_DEF_ "GenMsgCycleTime" 0;
BA_DEF_DEF_ "GenMsgILSupport" "Yes";
BA_DEF_DEF_ "GenMsgSendType" "Cyclic";
BA_DEF_DEF_ "GenSigStartValue" 0;
BA_DEF_DEF_ "NmBaseAddress" 1024;
BA_DEF_DEF_ "VFrameFormat" "StandardCAN";

BA_ "BusType"   "CAN FD";
BA_ "DBName"   "ADASACAN";

BA_ "GenMsgCycleTime" BO_ 1684 500;
BA_ "VFrameFormat" BO_ 1684 14;
BA_ "GenMsgCycleTime" BO_ 759 100;
BA_ "VFrameFormat" BO_ 759 14;
BA_ "GenMsgCycleTime" BO_ 353 10;
BA_ "VFrameFormat" BO_ 353 14;
BA_ "GenMsgCycleTime" BO_ 906 100;
BA_ "VFrameFormat" BO_ 906 14;
BA_ "GenMsgCycleTime" BO_ 80 500;
BA_ "VFrameFormat" BO_ 80 14;
BA_ "GenMsgCycleTime" BO_ 648 40;
BA_ "VFrameFormat" BO_ 648 14;
BA_ "GenMsgCycleTime" BO_ 651 40;
BA_ "VFrameFormat" BO_ 651 14;
BA_ "GenMsgCycleTime" BO_ 680 100;
BA_ "VFrameFormat" BO_ 680 14;
BA_ "GenMsgCycleTime" BO_ 722 100;
BA_ "VFrameFormat" BO_ 722 14;
BA_ "GenMsgCycleTime" BO_ 734 50;
BA_ "VFrameFormat" BO_ 734 14;
BA_ "GenMsgCycleTime" BO_ 378 10;
BA_ "VFrameFormat" BO_ 378 14;
BA_ "GenMsgCycleTime" BO_ 706 10;
BA_ "VFrameFormat" BO_ 706 14;
BA_ "GenMsgCycleTime" BO_ 450 10;
BA_ "VFrameFormat" BO_ 450 14;
BA_ "GenMsgCycleTime" BO_ 523 10;
BA_ "VFrameFormat" BO_ 523 14;
BA_ "GenMsgCycleTime" BO_ 962 100;
BA_ "VFrameFormat" BO_ 962 14;
BA_ "GenMsgCycleTime" BO_ 368 10;
BA_ "VFrameFormat" BO_ 368 14;
BA_ "GenMsgCycleTime" BO_ 384 10;
BA_ "VFrameFormat" BO_ 384 14;
BA_ "GenMsgCycleTime" BO_ 382 10;
BA_ "VFrameFormat" BO_ 382 14;
BA_ "GenMsgCycleTime" BO_ 591 20;
BA_ "VFrameFormat" BO_ 591 14;
BA_ "GenMsgCycleTime" BO_ 580 20;
BA_ "VFrameFormat" BO_ 580 14;
BA_ "GenMsgCycleTime" BO_ 786 100;
BA_ "VFrameFormat" BO_ 786 14;
BA_ "GenMsgCycleTime" BO_ 794 100;
BA_ "VFrameFormat" BO_ 794 14;
BA_ "GenMsgCycleTime" BO_ 775 100;
BA_ "VFrameFormat" BO_ 775 14;
BA_ "GenMsgCycleTime" BO_ 442 10;
BA_ "VFrameFormat" BO_ 442 14;
BA_ "GenMsgCycleTime" BO_ 1287 50;
BA_ "VFrameFormat" BO_ 1287 14;
BA_ "GenMsgCycleTime" BO_ 957 100;
BA_ "VFrameFormat" BO_ 957 14;
BA_ "GenMsgCycleTime" BO_ 632 10;
BA_ "VFrameFormat" BO_ 632 14;
BA_ "GenMsgCycleTime" BO_ 1426 1000;
BA_ "VFrameFormat" BO_ 1426 14;
BA_ "GenMsgCycleTime" BO_ 1393 1000;
BA_ "VFrameFormat" BO_ 1393 14;
BA_ "GenMsgCycleTime" BO_ 943 100;
BA_ "VFrameFormat" BO_ 943 14;

BA_ "GenSigStartValue" SG_ 353 VcuGearPosn 3;
BA_ "GenSigStartValue" SG_ 680 TmsAcEnvtlT 255;
BA_ "GenSigStartValue" SG_ 378 EPB_AchievedClampForce 29;
BA_ "GenSigStartValue" SG_ 450 MbRgnTarWhl 32768;
BA_ "GenSigStartValue" SG_ 368 EPS_ActualTorsionBarTorq 1024;
BA_ "GenSigStartValue" SG_ 368 EPS_MaxSafetyTorsionBarTorq 1024;
BA_ "GenSigStartValue" SG_ 368 EPS_MinSafetyTorsionBarTorq 1024;
BA_ "GenSigStartValue" SG_ 368 EPS_ActualMotorTorq 2048;
BA_ "GenSigStartValue" SG_ 382 EPS_MeasuredTorsionBarTorque 2048;
BA_ "GenSigStartValue" SG_ 382 EPS_Pinionang 7200;
BA_ "GenSigStartValue" SG_ 591 EPS_SteeringTorque 127;
BA_ "GenSigStartValue" SG_ 591 EpsSteerModFb 3;
BA_ "GenSigStartValue" SG_ 580 ACC_ACCTargetAcceleration 100;
BA_ "GenSigStartValue" SG_ 786 ACC_ACCTargetID 15;
BA_ "GenSigStartValue" SG_ 775 ACC_ACCTargetDirection 5;
BA_ "GenSigStartValue" SG_ 775 ACC_ACCTargetLatRange 500;
BA_ "GenSigStartValue" SG_ 775 ACC_ACCTargetLngRange 511;
BA_ "GenSigStartValue" SG_ 775 ACC_ACCTargetRelSpd 250;
BA_ "GenSigStartValue" SG_ 442 ACC_LatAngReq 7200;
BA_ "GenSigStartValue" SG_ 442 ACC_MotorTorqueMaxLimitRequest 1024;
BA_ "GenSigStartValue" SG_ 442 ACC_MotorTorqueMinLimitRequest 1024;
BA_ "GenSigStartValue" SG_ 632 ESP_LatAccel 3200;
BA_ "GenSigStartValue" SG_ 632 ESP_LongAccel 3200;

VAL_ 759 TboxLocalTiVld 0 "Valid" 1 "Invalid ";
VAL_ 353 VCUAccPedShield 0 "Unshield" 1 "Shield";
VAL_ 353 VCUAPAdriverInterruption 0 "No Interruption" 1 "Interruption" 2 "Reserved" 3 "invalid";
VAL_ 353 VCUAPARequestEnable 0 "norequest" 1 "Controlenabled" 2 "Control disable" 3 "invalid";
VAL_ 353 VCUShiftPostionValid 0 "Valid" 1 "Invalid";
VAL_ 353 VcuAccrMod 0 "invalid" 1 "Normal" 2 "Fast" 3 "Slow";
VAL_ 353 VcuAccrPedlPosnVld 0 "Valid" 1 "Invalid ";
VAL_ 353 VcuAPATorqRequestAvailable 0 "not available" 1 "available";
VAL_ 353 VcuCalcnAccrPedlPosnVld 0 "Valid" 1 "Invalid ";
VAL_ 353 VcuComFltSts 0 "no error" 1 "reversible error" 2 "irreversible error" 3 "not defined";
VAL_ 353 VcuEnyRecyclMod 0 "Not set" 1 "normal" 2 "strong";
VAL_ 353 VcuGearPosn 0 "Invalid" 1 "P" 2 "R" 3 "N" 4 "D" 5 "reserved";
VAL_ 353 VcuOvrdModReq 0 "Not override" 1 "Override";
VAL_ 353 VcuPtTqLimMaxVld 0 "Valid" 1 "Invalid ";
VAL_ 353 VcuPtTqLimMinVld 0 "Valid" 1 "Invalid ";
VAL_ 353 VcuPtTqRealVld 0 "Valid" 1 "Invalid ";
VAL_ 353 VcuPtTqReqAvl 0 "not available" 1 "available" 2 "available degraded";
VAL_ 353 VcuRdySts 0 "no Ready" 1 "Ready";
VAL_ 353 VcuShiftLvlPosn 0 "Center" 1 "Up" 2 "Down" 3 "Up,Up" 4 "Down,Down" 15 "Invalid";
VAL_ 353 VcuVehGearPosnVld 0 "Valid" 1 "Invalid ";
VAL_ 353 VcuVehWhlReqTqVld 0 "Valid" 1 "Invalid ";
VAL_ 906 VcuCrsDstSwtPlusSts 0 "按键未按下" 1 "按键按下" 2 "预留" 3 "Error";
VAL_ 906 VcuCrsResuSwtSts 0 "按键未按下" 1 "按键按下" 2 "预留" 3 "Error";
VAL_ 906 VcuCrsSetSwtSts 0 "按键未按下" 1 "按键按下" 2 "预留" 3 "Error";
VAL_ 906 VcuCrsSwtDiagInfo 0 "Reset" 1 "Variants of wrong information(变种信息错误)" 2 "voltage is higher than 16V(电源高于16V)" 3 "voltage is lower than 9V(电源低于9V)" 7 "invalid";
VAL_ 906 VcuCrsDstSwtReduceSts 0 "按键未按下" 1 "按键按下" 2 "预留" 3 "Error";
VAL_ 80 SrsCrashOutpSts 0 "NoCrash" 1 "crash";
VAL_ 80 SrsDrvrBucSwtSts 0 "Buckled" 1 "Unbuckle" 2 "NotUsed" 3 "NotUsed";
VAL_ 80 SrsWarnLampSts 0 "Lampoff" 1 "Lampon" 2 "LampFlashing" 3 "NotUsed";
VAL_ 80 SrsPassBucSwtSts 0 "Buckled" 1 "Unbuckle" 2 "NotUsed" 3 "NotUsed";
VAL_ 648 BcmAutHeadLiSts 0 "NotActived" 1 "Actived";
VAL_ 648 BcmDrvrDoorSts 0 "Close" 1 "Open";
VAL_ 648 BcmFrntFogLmpSts 0 "OFF" 1 "ON" 2 "Notused" 3 "Reserved";
VAL_ 648 BcmFrntWiperSts 0 "Off" 1 "Low" 2 "High" 3 "Error";
VAL_ 648 BcmHiBeamSts 0 "OFF" 1 "ON" 2 "Notused" 3 "Reserved";
VAL_ 648 BcmLeReDoorSts 0 "Close" 1 "Open";
VAL_ 648 BcmLoBeamSts 0 "OFF" 1 "ON" 2 "Notused" 3 "Reserved";
VAL_ 648 BcmPassDoorSts 0 "Close" 1 "Open";
VAL_ 648 BcmReFoglmpSts 0 "OFF" 1 "ON" 2 "Notused" 3 "Error";
VAL_ 648 BcmRiReDoorSts 0 "Close" 1 "Open";
VAL_ 648 BcmStsRainSnsr 0 "NOerror" 1 "Error";
VAL_ 648 BcmTurnIndcrLe 0 "OFF" 1 "ON" 2 "Notused" 3 "Error";
VAL_ 648 BcmTurnIndcrRi 0 "OFF" 1 "ON" 2 "Notused" 3 "Error";
VAL_ 648 BcmLiSnsrFlt 0 "NOerror" 1 "Error";
VAL_ 648 BcmEmgyLiSts 0 "OFF" 1 "ON" 2 "Notused" 3 "Error（故障）";
VAL_ 648 BcmPwrStsFb 0 "Off" 1 "FBLpower" 2 "ON" 3 "Start";
VAL_ 651 BCM_TurnLightSwitchSts 0 "Not Actived" 1 "Left Actived" 2 "Right Actived" 3 "Invalid";
VAL_ 651 BCM_BrakeLampError 0 "无故障" 1 "有故障";
VAL_ 651 BCM_BrakeLampStatus 0 "OFF" 1 "ON" 2 "Not used" 3 "Reserved";
VAL_ 651 BCM_HighBeamLampError 0 "No error" 1 "error";
VAL_ 651 BCM_LeftLowBeamError 0 "无故障" 1 "有故障";
VAL_ 651 BCM_RightLowBeamError 0 "无故障" 1 "有故障";
VAL_ 651 BCM_SunroofStatus 0 "Close" 1 "Open";
VAL_ 651 BCM_TurnIndicatorLeftError 0 "无故障" 1 "有故障";
VAL_ 651 BCM_TurnIndicatorRightError 0 "无故障" 1 "有故障";
VAL_ 651 PEPS_LockKeyStatus 0 "invalid" 1 "pressed" 2 "not pressed " 3 "reserve";
VAL_ 651 PEPS_TrunkKeyStatus 0 "invalid" 1 "pressed" 2 "not pressed " 3 "reserve";
VAL_ 651 PEPS_UnLockKeyStatus 0 "invalid" 1 "pressed" 2 "not pressed " 3 "reserve";
VAL_ 680 TmsAcEnvtlTVld 0 "Valid" 1 "Invalid";
VAL_ 680 TmsFrntBlowMod 0 "blow face" 1 "blow face/blow feet" 2 "blow feet" 3 "blow fee/defroster" 4 "defroster" 7 "error";
VAL_ 734 IP_DISFail 0 "no error" 1 "error";
VAL_ 734 IP_QDashACCFail 0 "no error" 1 "error" 2 "reserved" 3 "reserved";
VAL_ 378 EspVehSpdVld 0 "Valid" 1 "Invalid";
VAL_ 378 EPB_APArequest_Available 0 "notavailable" 1 "available";
VAL_ 378 EPB_FailStatuss_Primary 0 "no error in EPB " 1 "not defined  " 2 "not defined" 3 "error in EPB ";
VAL_ 706 IBBrkPedlModSts 0 "舒适模式" 1 "运动模式" 2 "Reserved" 3 "Reserved";
VAL_ 706 IbBrkPedlStsGb 0 "制动未踩下" 101 "制动踩下";
VAL_ 706 IbBrkPedlStsGbVld 0 "NotInitialized" 1 "Normal" 2 "Invalid";
VAL_ 706 IBCU_PFSBrakePressureValid 0 "Invalid" 1 "Valid";
VAL_ 706 IBCU_PlungerBrakePressureValid 0 "Invalid" 1 "Valid";
VAL_ 706 IBBrkPedlModSwtAvl 0 "display" 1 "No display";
VAL_ 450 EspEbdFailr 0 "No error" 1 "Error";
VAL_ 450 EspAbsActv 0 "Not active" 1 "active";
VAL_ 450 EspAbsFailr 0 "No error" 1 "Error";
VAL_ 450 EspActvSts 0 "Not active" 1 "active";
VAL_ 450 EspFctOpenSts 0 "Off" 1 "ON";
VAL_ 450 EspTcsFailr 0 "No error" 1 "Error";
VAL_ 450 EspReWhlDecTarTqActv 0 "Not active" 1 "active";
VAL_ 450 EspReWhlIncTarTqActv 0 "Not active" 1 "active";
VAL_ 450 EspVehStandstill 0 "Not standstill" 1 "standstill";
VAL_ 450 MbRgnTarWhlQlfr 0 "NotIntialized" 1 "Normal" 2 "Faulty";
VAL_ 450 EspAutoHoldActvSts 0 "Not active" 1 "active";
VAL_ 450 IBCU_BrakeDiscHighTempWarning 0 "no failure" 1 "OverheatLevel1" 2 "OverheatLevel2" 3 "reserved";
VAL_ 450 EspBrkLiOnReq 0 "Not request(brakelightOFF)" 1 "brake light ON" 2 "Not used" 3 "signal Not available";
VAL_ 450 EspVdcActvSts 0 "Not active" 1 "active";
VAL_ 450 EspTcsActvSts 0 "Not active" 1 "active";
VAL_ 450 IBCU_ADCReducedFuncAvail 0 "not Available" 1 "Available" 2 "reserved" 3 "reserved";
VAL_ 450 IBCU_ADCFullFuncAvail 0 "not Available" 1 "Available" 2 "SafeControl Avail" 3 "reserved";
VAL_ 450 IBCU_CommunicationInvalid 0 "noerror" 1 "error" 2 "reserved" 3 "reserved";
VAL_ 450 IBCU_ADCActiveState 0 "ADC_NotActive" 1 "ADC_ActiveReduce" 2 "ADC_ActiveFull" 3 "reserved";
VAL_ 523 ESP_BrakeForce 0 "nobrakeforce" 1 "havebrakeforce";
VAL_ 523 ESP_PrefillActive 0 "notactive" 1 "active";
VAL_ 523 ESP_PrefillAvailable 0 "notavailable" 1 "available";
VAL_ 523 IBCU_APCActiveStatus 0 " Deactive" 1 " ReducedFunction Active" 2 " FullFunction Active" 3 " Reserved";
VAL_ 523 IBCU_APCReducedFuncAvail 0 "notavailable" 1 "available";
VAL_ 523 IBCU_APCFullFuncAvail 0 "notavailable" 1 "available" 2 "testpending";
VAL_ 523 ESP_APA_CDDAPVehicleHold 0 "Flase" 1 "True";
VAL_ 523 ESP_APA_DriverOverride 0 "Flase" 1 "True";
VAL_ 523 ESP_ABAactive 0 "notactive" 1 "active";
VAL_ 523 ESP_ABAavailable 0 "notavailable" 1 "available";
VAL_ 523 ESP_AEBAvailable 0 "notavailable" 1 "available";
VAL_ 523 ESP_AEBdecActive 0 "notactive" 1 "active";
VAL_ 523 ESP_AWBactive 0 "notactive" 1 "active";
VAL_ 523 ESP_AWBavailable 0 "notavailable" 1 "available";
VAL_ 523 ESP_BrakeOverHeatBrakeDiscTemp 0 "nothigh" 1 "temptoohigh";
VAL_ 523 ESP_QDCACC 0 "noerror" 1 "error" 2 "reserved" 3 "reserved";
VAL_ 523 WhlSpdLeFrntDir 0 "Forward" 1 "backward" 2 "Standstill" 3 "Invalid";
VAL_ 523 WhlSpdLeReDir 0 "Forward" 1 "backward" 2 "Standstill" 3 "Invalid";
VAL_ 523 WhlSpdRiFrntDir 0 "Forward" 1 "backward" 2 "Standstill" 3 "Invalid";
VAL_ 523 WhlSpdRiReDir 0 "Forward" 1 "backward" 2 "Standstill" 3 "Invalid";
VAL_ 523 WhlSpdLeFrntDataVld 0 "Valid" 1 "Invalid ";
VAL_ 523 WhlSpdLeReDataVld 0 "Valid" 1 "Invalid ";
VAL_ 523 WhlSpdRiFrntDataVld 0 "Valid" 1 "Invalid ";
VAL_ 523 WhlSpdRiReDataVld 0 "Valid" 1 "Invalid ";
VAL_ 523 ESP_UrgencyBrakeAlarm 0 "NotActive" 1 "Active";
VAL_ 523 ESP_CDD_Active 0 "notactive" 1 "active";
VAL_ 523 ESP_CDD_Available 0 "notavailable" 1 "available";
VAL_ 962 EpbFailrSts 0 "No error" 1 "Not defined" 2 "Not defined" 3 "error";
VAL_ 962 EpbSts 0 "both brakes released" 1 "both brakes applied" 2 "both brakes Releasing" 3 "both brakes Locking" 4 "unknown";
VAL_ 962 EspEpbReqAvl 0 "Not available" 1 "available";
VAL_ 962 EpbStsPrimary 0 "released" 1 " ParkedApplied" 2 "releasing" 3 "Locking" 4 "unknown" 5 "HoldApplied" 6 " CompletelyReleased" 7 "HapPrepared";
VAL_ 368 EPS_fault_state 0 "No Fault" 1 "Thermal Protection Fault" 2 "Power Limit Fault" 3 "IMC Result error" 4 "Torque Sensor Fault(recoverable with assist)" 5 "Angle Sensor Fault(recoverable with assist)" 6 "Sensorless Angle Fault(Non recoverable without assist)" 7 "Power Supply Fault(Non recoverable)" 8 "Motor Sensor Fault(Non recoverable)" 9 "Flash/RAM/NVM Fault(Non recoverable)" 10 "Battery Voltage Fault(Recoverable)" 11 "ECU ID Fault(Non recoverable)" 12 "Other Fault(Non recoverable)";
VAL_ 384 EpsSasCalSts 0 "Calibrated" 1 "Not Calibrated";
VAL_ 384 EpsSasSteerAgVld 0 "Valid" 1 "Invalid";
VAL_ 384 EpsSteerAgSensFilr 0 "Valid" 1 "Invalid";
VAL_ 382 EPS_LatCtrlActive 0 "Not Actived" 1 "Actived";
VAL_ 382 EPS_LatCtrlAvailabilityStatus 0 "not Availability" 1 "Availability" 2 "failure" 3 "reserved";
VAL_ 382 EPS_MeasuredTorsionBarTorqValid 0 "可用" 1 "不可用";
VAL_ 382 EPS_Handwheel_Relang_Valid 0 "valid" 1 "invalid";
VAL_ 382 EPS_Pinionang_Valid 0 "valid" 1 "invalid";
VAL_ 382 EPS_ADS_Abortfeedback 0 "No Fault" 1 "Adas Speed Invalid" 2 "Adas Signal Invalid" 3 "State Mismatch" 4 "APA Interrupt" 5 "BUS Off" 6 "Both Channels CAN down" 7 "Adas Chassis CAN Down" 8 "ADAS Internal Error" 9 "Speed out of range" 10 "AgAmpErr" 11 "AgGrdtFlt" 12 "Driver Interrupt" 13 "ADAS Req Mode Invld";
VAL_ 591 EPS_ConcussAvailabilityStatus 0 "Concuss Availability震动可用但是未震动" 1 "Concuss Active震动激活中" 2 "EPS Concuss failureEPS震动故障不可用" 3 "reserved";
VAL_ 591 EPS_IACC_abortreason 0 "NO_DRIVING_INTERUPTION" 1 "DRIVER_RECOVERY(Over ride)" 2 "VEHICLE_SPEED ERROR" 3 "REQUEST ERROR" 4 "DAE_THERMAL_SECURITY" 5 "OTHER_DEFAULT" 6 "ADAS MESSAGE FAULT" 7 "RESERVED";
VAL_ 591 EPS_TorqSensorStatus 0 "Normal" 1 "Abnormal";
VAL_ 591 EpsSteerModFb 0 "Standar Mode" 1 "Comfort Mode" 2 "Sport Mode" 3 "unknow";
VAL_ 591 EpsFaild 0 "No failure" 1 "Slight failure" 2 "Critical failure" 3 "Fatal failure";
VAL_ 591 EPS_LDW_ShakeLevStatus 0 "reserved" 1 "low" 2 "normal" 3 "high";
VAL_ 591 EPS_SystemSt 0 "disable" 1 "off" 2 "enable" 3 "warm int";
VAL_ 591 EPS_ADS_ControlFeedback 0 "Standby" 1 "Parking Running" 2 "AutoDriving" 3 "ESS Runing";
VAL_ 591 EPS_ModeSwitchSt 0 "No judgment" 1 "In judgment";
VAL_ 591 EPS_APA_EpasFAILED 0 "No Fail" 1 "Fail";
VAL_ 580 ACC_AccTrqReqActive 0 "not Active" 1 "Active.";
VAL_ 580 ACC_LatTakeoverReq 0 "no request" 1 "level 1 request" 2 "level 2 request" 3 "reserved";
VAL_ 580 ACC_ACCMode 0 "OFF mode" 1 "Passive mode" 2 "StandBy mode" 3 "Active Control mode" 4 "Brake Only mode" 5 "Override" 6 "Stand Wait mode" 7 "Failure mode";
VAL_ 580 ACC_CDDActive 0 "not active" 1 "Active";
VAL_ 580 ACC_DecToStop 0 "no demand" 1 "demand";
VAL_ 580 ACC_Driveoff_Request 0 "No request" 1 "request";
VAL_ 580 ACC_LngTakeOverReq 0 "no request" 1 "level 1 request" 2 "level 2 request" 3 "reserved";
VAL_ 580 ACC_AWBlevel 0 "no level" 1 "level 1" 2 "level 2" 3 "level 3" 4 "level 4";
VAL_ 580 ACC_TakeOverReq 0 "无请求" 1 "1级接管请求" 2 "2级接管请求" 3 "3级接管请求";
VAL_ 794 ACC_DriverHandsOffStatus 0 "hands off" 1 "hands on Level1" 2 "hand on Level2" 3 "unkown";
VAL_ 794 ACC_HandsOnReq 0 "no request" 1 "level 1 request" 2 "level 2 request" 3 "level 3 request" 4 "level 4 request";
VAL_ 794 ACC_HostLaneLeftStatus 0 "No display" 1 "Tracking" 2 "Intervention" 3 "Warning" 4 "Centering" 5 "Crossing" 6 "UDLC Request Active" 7 "reserved" 8 "UDLC Not Active By Obj";
VAL_ 794 ACC_HostLaneRightStatus 0 "No display" 1 "Tracking" 2 "Intervention" 3 "Warning" 4 "Centering" 5 "Crossing" 6 "UDLC Request Active" 7 "reserved" 8 "UDLC Not Active By Obj";
VAL_ 794 ACC_IACCHWAMode 0 "off" 1 "standby" 2 "passive" 3 "active" 4 "suspend" 5 "prohibition" 6 "reserved" 7 "failure";
VAL_ 794 ACC_IACCHWATextInfoForDriver 0 "no display" 31 "reserved";
VAL_ 794 ACC_TargetBasedLateralControl 0 "no lateral control" 1 "around Based" 2 "lane based" 3 "target based";
VAL_ 794 ACC_Voiceinfo 0 "no voice" 1 "latentWarning voive" 2 "FCW/AEB voice" 3 "ACC object detect voice" 4 "ACC object disappeared voice" 5 "ACC/IACC takeover request voice" 6 "Lane Left dangerous warning  voice" 7 "Lane Right dangerous warning  voice" 8 "reserved" 9 "IACC Active voice" 10 "IACC exit voice" 11 "reserved" 12 "reserved" 13 "cruise unintended exit" 14 "TrafficWarning";
VAL_ 794 ACC_EmergencyLightingRequest 0 "no request" 1 "Level1" 2 "Level2" 3 "OFF";
VAL_ 775 ACC_ACCEPBrequest 0 "no request" 1 "request";
VAL_ 775 ACC_ACCTargetDirection 0 "Forward" 1 "OnComing" 2 "Left" 3 "Right" 4 "unknown" 5 "no display";
VAL_ 775 ACC_ACCTargetType 0 "no display" 1 "sedan" 2 "motorcycle" 3 "pedestrian" 4 "Bicycle" 5 "Bus" 6 "van" 7 "truck";
VAL_ 775 ACC_DistanceLevel 0 "no display" 1 "Level 1" 2 "Level 2" 3 "Level 3";
VAL_ 775 ACC_ObjValid 0 "no object" 1 "target object detected";
VAL_ 775 ACC_SaftyBelt_Tightened 0 "level0" 1 "level 1" 2 "level 2" 3 "Reserved";
VAL_ 775 ACC_SaftyBeltVibrationReq 0 "No Request" 1 "Request";
VAL_ 775 ACC_TextInfoForDriver 0 "no display" 1 "unable to activate ACC" 2 "ACC active control is cancelled" 3 "ACC error by Front Radar" 4 "ACC temporary unavailable by others" 5 "EPB activate" 6 "No forward gear" 7 "Seatbelt unbuckled" 8 "Engine No Running" 9 "ESP off" 10 "bonnet is Open" 11 "Speed over 150kph" 12 "ACC Error by EMS/VCU/TCU" 13 "reserved" 14 "ACC Error by EPBI" 15 "ACC unintended exit warning" 16 "door is open" 17 "brake pedal is applied" 18 "speed reduce by ramp" 19 "speed reduce by tunnel" 20 "ACC error by Front Camera" 21 "speed reduce by condition" 22 "speed reduce by SpdLimited" 23 "reserved" 24 "speed reduce by Tollstation" 25 "ACC cannot active by snow mode" 26 "SteeringAngle is over" 27 "emergency brake suddenly";
VAL_ 775 ACC_TimeGapSet 0 "no display" 1 "1.0S" 2 "1.4S" 3 "1.8S" 4 "2.4S";
VAL_ 442 ACC_LatAngReqActive 0 "not Active" 1 "Active";
VAL_ 1287 HU_AutoBrakeEnable 0 "off" 1 "on";
VAL_ 1287 HU_FCWSetting 0 "Early" 1 "Normal" 2 "Late" 3 "Off";
VAL_ 1287 HU_HMAEnable 0 "off" 1 "on";
VAL_ 1287 HU_IACCEnable 0 "Inactive" 1 "Off" 2 "On" 3 "Reserved";
VAL_ 1287 HU_LASModeSelection 0 "Inactive" 1 "LDW" 2 "LKA" 3 "LCS";
VAL_ 1287 HU_LASWarningModeSelection 0 "inactive" 1 "visual" 2 "sound" 3 "vibration" 4 "sound and vibration";
VAL_ 1287 HU_VC_CruiseControl 0 "No Request" 1 "ACC Activate" 2 "ACC Resume" 3 "IACC Activate" 4 "IACC Resume" 5 "Cancel" 6 "Reserved" 7 "Invalid";
VAL_ 1287 HU_VC_CruiseSetDistance 0 "No Request" 1 "Level 1" 2 "Level 2" 3 "Level 3" 4 "Level 4" 5 "Forward Req" 6 "Backward Req" 7 "Invalid";
VAL_ 1287 HU_VC_CruiseSetSpeed 0 "No Request";
VAL_ 957 HU_ELKEnable 0 "Inactive" 1 "OFF" 2 "ON" 3 "Reserved";
VAL_ 632 ESP_YawRateValid 0 " Initializing" 1 " Valid" 2 " Invalid" 3 " Reserved";
VAL_ 632 ESP_LatAccelValid 0 "Initializing" 1 "Valid" 2 "Invalid" 3 "Reserved";
VAL_ 632 ESP_LongAccelValid 0 "Initializing" 1 "Valid" 2 "Invalid" 3 "Reserved";
VAL_ 632 ESP_IMUCalibrated 0 "Calibrated" 1 " Not Calibrated";
VAL_ 1426 FC_WakeUp_BYTE4BIT0 0 "Inactive" 1 "CAN网络管理报文唤醒";
VAL_ 1426 FC_WakeUp_BYTE4BIT1 0 "Inactive" 1 "IG唤醒";
VAL_ 1426 FC_NotSleep_BYTE7BIT0 0 "Inactive" 1 "CAN网络上其他节点不允许休眠";
VAL_ 1426 FC_NotSleep_BYTE7BIT1 0 "Inactive" 1 "IGN信号为ON档及以上";
VAL_ 1393 FCHwVers0 72 "H";
VAL_ 1393 FCHwVers1 87 "W";
VAL_ 1393 FCHwVers2 48 "0" 49 "1" 50 "2" 51 "3" 52 "4" 53 "5" 54 "6" 55 "7" 56 "8" 57 "9" 65 "A" 66 "B" 67 "C" 68 "D" 69 "E" 70 "F" 71 "G" 72 "H" 73 "I" 74 "J" 75 "K" 76 "L" 77 "M" 78 "N" 79 "O" 80 "P" 81 "Q" 82 "R" 83 "S" 84 "T" 85 "U" 86 "V" 87 "W" 88 "X" 89 "Y" 90 "Z";
VAL_ 1393 FCHwVers3 46 ".";
VAL_ 1393 FCHwVers4 48 "0" 49 "1" 50 "2" 51 "3" 52 "4" 53 "5" 54 "6" 55 "7" 56 "8" 57 "9" 65 "A" 66 "B" 67 "C" 68 "D" 69 "E" 70 "F" 71 "G" 72 "H" 73 "I" 74 "J" 75 "K" 76 "L" 77 "M" 78 "N" 79 "O" 80 "P" 81 "Q" 82 "R" 83 "S" 84 "T" 85 "U" 86 "V" 87 "W" 88 "X" 89 "Y" 90 "Z";
VAL_ 1393 FCHwVers5 46 ".";
VAL_ 1393 FCHwVers6 48 "0" 49 "1" 50 "2" 51 "3" 52 "4" 53 "5" 54 "6" 55 "7" 56 "8" 57 "9" 65 "A" 66 "B" 67 "C" 68 "D" 69 "E" 70 "F" 71 "G" 72 "H" 73 "I" 74 "J" 75 "K" 76 "L" 77 "M" 78 "N" 79 "O" 80 "P" 81 "Q" 82 "R" 83 "S" 84 "T" 85 "U" 86 "V" 87 "W" 88 "X" 89 "Y" 90 "Z";
VAL_ 1393 FCSwVers0 83 "S";
VAL_ 1393 FCSwVers1 87 "W";
VAL_ 1393 FCSwVers2 48 "0" 49 "1" 50 "2" 51 "3" 52 "4" 53 "5" 54 "6" 55 "7" 56 "8" 57 "9" 65 "A" 66 "B" 67 "C" 68 "D" 69 "E" 70 "F" 71 "G" 72 "H" 73 "I" 74 "J" 75 "K" 76 "L" 77 "M" 78 "N" 79 "O" 80 "P" 81 "Q" 82 "R" 83 "S" 84 "T" 85 "U" 86 "V" 87 "W" 88 "X" 89 "Y" 90 "Z";
VAL_ 1393 FCSwVers3 46 ".";
VAL_ 1393 FCSwVers4 48 "0" 49 "1" 50 "2" 51 "3" 52 "4" 53 "5" 54 "6" 55 "7" 56 "8" 57 "9" 65 "A" 66 "B" 67 "C" 68 "D" 69 "E" 70 "F" 71 "G" 72 "H" 73 "I" 74 "J" 75 "K" 76 "L" 77 "M" 78 "N" 79 "O" 80 "P" 81 "Q" 82 "R" 83 "S" 84 "T" 85 "U" 86 "V" 87 "W" 88 "X" 89 "Y" 90 "Z";
VAL_ 1393 FCSwVers5 46 ".";
VAL_ 1393 FCSwVers6 48 "0" 49 "1" 50 "2" 51 "3" 52 "4" 53 "5" 54 "6" 55 "7" 56 "8" 57 "9" 65 "A" 66 "B" 67 "C" 68 "D" 69 "E" 70 "F" 71 "G" 72 "H" 73 "I" 74 "J" 75 "K" 76 "L" 77 "M" 78 "N" 79 "O" 80 "P" 81 "Q" 82 "R" 83 "S" 84 "T" 85 "U" 86 "V" 87 "W" 88 "X" 89 "Y" 90 "Z";
SIG_GROUP_ 1684 Signal_Group_FC_694 1684 : LAS_DTC1_HighByte LAS_DTC1_LowByte LAS_DTC1_MiddByte LAS_DTC1_Status LAS_DTC2_HighByte LAS_DTC2_LowByte LAS_DTC2_MiddByte LAS_DTC2_Status;
SIG_GROUP_ 759 Signal_Group_TBOX_2F7 759 : TboxLocalTiDate TboxLocalTiHr TboxLocalTiMins TboxLocalTiMth TboxLocalTiSec TboxLocalTiVld TboxLocalTiYear;
SIG_GROUP_ 353 Signal_Group_VCU_161 353 : VCUAccPedShield VCUAPAdriverInterruption VCUAPARequestEnable VCUShiftPostionValid VcuAccrMod VcuAccrPedlPosn VcuAccrPedlPosnVld VcuAPATorqRequestAvailable VcuCalcnAccrPedlPosn VcuCalcnAccrPedlPosnVld VcuComFltSts VcuEnyRecyclMod VcuGearPosn VcuOvrdModReq VcuPtTqLimMax VcuPtTqLimMaxVld VcuPtTqLimMin VcuPtTqLimMinVld VcuPtTqReal VcuPtTqRealVld VcuPtTqReqAvl VcuRdySts VcuShiftLvlPosn VcuVehGearPosnVld VcuVehWhlReqTq VcuVehWhlReqTqVld VcuCrcChk161 VcuCycCntr161;
SIG_GROUP_ 906 Signal_Group_VCU_38A 906 : VcuCRCCheck_38A VcuCrsDstSwtPlusSts VcuCrsResuSwtSts VcuCrsSetSwtSts VcuRollingCounter_38A VcuCrsSwtDiagInfo VcuCrsDstSwtReduceSts;
SIG_GROUP_ 80 Signal_Group_GW_50 80 : SrsCrcChk050 SrsCycCntr050 SrsCrashOutpSts SrsCrashOutpStsChks SrsDrvrBucSwtSts SrsWarnLampSts SrsPassBucSwtSts;
SIG_GROUP_ 648 Signal_Group_GW_288 648 : BcmAutHeadLiSts BcmCrcChk288 BcmCycCntr288 BcmDrvrDoorSts BcmFrntFogLmpSts BcmFrntWiperSts BcmHiBeamSts BcmLeReDoorSts BcmLoBeamSts BcmPassDoorSts BcmReFoglmpSts BcmRiReDoorSts BcmStsRainSnsr BcmTurnIndcrLe BcmTurnIndcrRi BcmLiSnsrFlt BcmEmgyLiSts BcmPwrStsFb;
SIG_GROUP_ 651 Signal_Group_GW_28B 651 : BCM_RollingCounter_28B BCM_CRCCheck_28B BCM_TurnLightSwitchSts BCM_BrakeLampError BCM_BrakeLampStatus BCM_HighBeamLampError BCM_LeftLowBeamError BCM_RightLowBeamError BCM_SunroofStatus BCM_TurnIndicatorLeftError BCM_TurnIndicatorRightError PEPS_LockKeyStatus PEPS_TrunkKeyStatus PEPS_UnLockKeyStatus;
SIG_GROUP_ 680 Signal_Group_GW_2A8 680 : TmsActPwr TmsAcEnvtlT TmsAcEnvtlTVld TmsFrntBlowMod TmsCrcChk2A8 TmsCycCntr2A8;
SIG_GROUP_ 722 Signal_Group_GW_2D2 722 : CdcTotMilg;
SIG_GROUP_ 734 Signal_Group_GW_2DE 734 : IP_CRCCheck_2DE IP_DISFail IP_QDashACCFail IP_RollingCounter_2DE;
SIG_GROUP_ 378 Signal_Group_GW_17A 378 : EspVehSpdVld WheelPressureRearRight_Model WheelPressureFrontRight_Model WheelPressureRearLeft_Model WheelPressureFrontLeft_Model ESP_RollingCounter_17A ESP_CRCCheck_17A EPB_APArequest_Available EPB_FailStatuss_Primary EPB_AchievedClampForce_Primary EPB_AchievedClampForce EspVehSpd;
SIG_GROUP_ 706 Signal_Group_GW_2C2 706 : IBCU_PFSBrakePressure IBCU_PlungerBrakePressure IBBrkPedlModSts IbBrkPedlStsGb IbBrkPedlStsGbVld IbCrcChk2C2 IbCycCntr2C2 IBCU_PFSBrakePressureValid IBCU_PlungerBrakePressureValid IBBrkPedlModSwtAvl;
SIG_GROUP_ 450 Signal_Group_GW_1C2 450 : EspEbdFailr EspAbsActv EspAbsFailr EspActvSts EspFctOpenSts EspTcsFailr EspReWhlDecTarTqActv EspReWhlIncTarTqActv EspVehStandstill EspReWhlDecTarTq MbRgnTarWhl MbRgnTarWhlQlfr EspReWhlIncTarTq EspAutoHoldActvSts IBCU_BrakeDiscHighTempWarning EspCrcChk1C2 EspCycCntr1C2 EspBrkLiOnReq EspVdcActvSts EspTcsActvSts IBCU_ADCReducedFuncAvail IBCU_ADCFullFuncAvail IBCU_CommunicationInvalid IBCU_ADCActiveState;
SIG_GROUP_ 523 Signal_Group_GW_20B 523 : ESP_BrakeForce ESP_PrefillActive ESP_PrefillAvailable IBCU_APCActiveStatus IBCU_APCReducedFuncAvail IBCU_APCFullFuncAvail ESP_APA_CDDAPVehicleHold ESP_APA_DriverOverride ESP_ABAactive ESP_ABAavailable ESP_AEBAvailable ESP_AEBdecActive ESP_AWBactive ESP_AWBavailable ESP_BrakeOverHeatBrakeDiscTemp ESP_QDCACC WhlSpdFrntLePls WhlSpdFrntRiPls WhlSpdReLePls WhlSpdReRiPls WhlSpdLeFrntDir WhlSpdLeReDir WhlSpdRiFrntDir WhlSpdRiReDir WhlSpdLeFrntData WhlSpdLeFrntDataVld WhlSpdLeReData WhlSpdLeReDataVld WhlSpdRiFrntData WhlSpdRiFrntDataVld WhlSpdRiReData WhlSpdRiReDataVld ESP_UrgencyBrakeAlarm ESP_CDD_Active ESP_CDD_Available IbcuCrcChk20B IbcuCycCntr20B IBCU_ADCRampOffSuspendState ESP_Vehicle_Speed_Reference;
SIG_GROUP_ 962 Signal_Group_GW_3C2 962 : EpbFailrSts EpbSts EspCrcChk3C2 EspCycCntr3C2 EspEpbReqAvl EpbStsPrimary;
SIG_GROUP_ 368 Signal_Group_GW_170 368 : EPS_ActualTorsionBarTorq EPS_CRCCheck_170 EPS_MaxSafetyTorsionBarTorq EPS_MinSafetyTorsionBarTorq EPS_RollingCounter_170 EPS_ActualMotorTorq EPS_fault_state;
SIG_GROUP_ 384 Signal_Group_GW_180 384 : EpsSasCalSts EpsSasSteerAg EpsSasSteerAgVld EpsSteerAgRate EpsSteerAgSensFilr EpsCrcChk180 EpsCycCntr180;
SIG_GROUP_ 382 Signal_Group_GW_17E 382 : EPS_CRCCheck_17E EPS_LatCtrlActive EPS_LatCtrlAvailabilityStatus EPS_MeasuredTorsionBarTorque EPS_MeasuredTorsionBarTorqValid EPS_RollingCounter_17E EPS_Pinionang EPS_Handwheel_Relang EPS_Handwheel_Relang_Valid EPS_Pinionang_Valid EPS_ADS_Abortfeedback;
SIG_GROUP_ 591 Signal_Group_GW_24F 591 : EPS_ConcussAvailabilityStatus EPS_CRCCheck_24F EPS_IACC_abortreason EPS_RollingCounter_24F EPS_SteeringTorque EPS_TorqSensorStatus EpsSteerModFb EpsFaild EPS_LDW_ShakeLevStatus EPS_SystemSt EPS_ADASActiveMode EPS_ADS_ControlFeedback EPS_ModeSwitchSt EPS_ElectPowerConsumption EPS_APA_EpasFAILED;
SIG_GROUP_ 580 Signal_Group_FC_244 580 : ACC_AccTrqReq ACC_AccTrqReqActive ACC_LatTakeoverReq ACC_ACCMode ACC_ACCTargetAcceleration ACC_CDDActive ACC_CRCCheck_24E ACC_CRCCheck_25E ACC_DecToStop ACC_Driveoff_Request ACC_RollingCounter_24E ACC_RollingCounter_25E ADS_RollingCounter_244 ADS_CRCCheck_244 ACC_LngTakeOverReq ACC_AWBlevel ACC_TakeOverReq;
SIG_GROUP_ 786 Signal_Group_FC_312 786 : ADS_RollingCounter_312 ADS_CRCCheck_312 ACC_ACCTargetID ACC_CRCCheck_3E4 ACC_RollingCounter_3E4;
SIG_GROUP_ 794 Signal_Group_FC_31A 794 : ACC_DriverHandsOffStatus ACC_HandsOnReq ACC_HostLaneLeftStatus ACC_HostLaneRightStatus ACC_IACCHWAMode ACC_IACCHWATextInfoForDriver ACC_RollingCounter_30D ACC_CRCCheck_30D ACC_RollingCounter_367 ACC_CRCCheck_367 ACC_RollingCounter_36D ACC_CRCCheck_36D ACC_TargetBasedLateralControl ACC_Voiceinfo ACC_RollingCounter_31A ACC_CRCCheck_31A ACC_RollingCounter_30A ACC_CRCCheck_30A ACC_EmergencyLightingRequest;
SIG_GROUP_ 775 Signal_Group_FC_307 775 : ACC_RollingCounter_307 ACC_CRCCheck_307 ACC_ACCEPBrequest ACC_ACCTargetDirection ACC_ACCTargetLatRange ACC_ACCTargetLngRange ACC_ACCTargetRelSpd ACC_ACCTargetType ACC_CRCCheck_322 ACC_CRCCheck_344 ACC_CRCCheck_35E ACC_CRCCheck_35F ACC_DistanceLevel ACC_ObjValid ACC_RollingCounter_322 ACC_RollingCounter_344 ACC_RollingCounter_35E ACC_RollingCounter_35F ACC_SaftyBelt_Tightened ACC_SaftyBeltVibrationReq ACC_SetSpeed ACC_TextInfoForDriver ACC_TimeGapSet;
SIG_GROUP_ 442 Signal_Group_FC_1BA 442 : ACC_CRCCheck_1BA_0 ACC_LatAngReq ACC_LatAngReqActive ACC_MotorTorqueMaxLimitRequest ACC_MotorTorqueMinLimitRequest ACC_RollingCounter_1BA_1 ACC_CRCCheck_1BA_1 ACC_RollingCounter_1BA_0;
SIG_GROUP_ 1287 Signal_Group_GW_507 1287 : HU_AutoBrakeEnable HU_FCWSetting HU_HMAEnable HU_IACCEnable HU_LASModeSelection HU_LASWarningModeSelection HU_VC_CruiseControl HU_VC_CruiseSetDistance HU_VC_CruiseSetSpeed;
SIG_GROUP_ 957 Signal_Group_GW_3BD 957 : HU_ELKEnable;
SIG_GROUP_ 632 Signal_Group_GW_278 632 : ESP_LatAccel ESP_LongAccel ESP_YawRateValid ESP_YawRate ESP_RollingCounter_278 ESP_CRCCheck_278 ESP_LatAccelValid ESP_LongAccelValid ESP_IMUCalibrated;
SIG_GROUP_ 1426 Signal_Group_FC_592 1426 : FC_WakeUp_BYTE4BIT0 FC_WakeUp_BYTE4BIT1 FC_NotSleep_BYTE7BIT0 FC_NotSleep_BYTE7BIT1;
SIG_GROUP_ 1393 Signal_Group_FC_571 1393 : FCHwVers0 FCHwVers1 FCHwVers2 FCHwVers3 FCHwVers4 FCHwVers5 FCHwVers6 FCSwVers0 FCSwVers1 FCSwVers2 FCSwVers3 FCSwVers4 FCSwVers5 FCSwVers6;
SIG_GROUP_ 943 Signal_Group_GW_3AF 943 : HU_NavCurrentRoadType;
